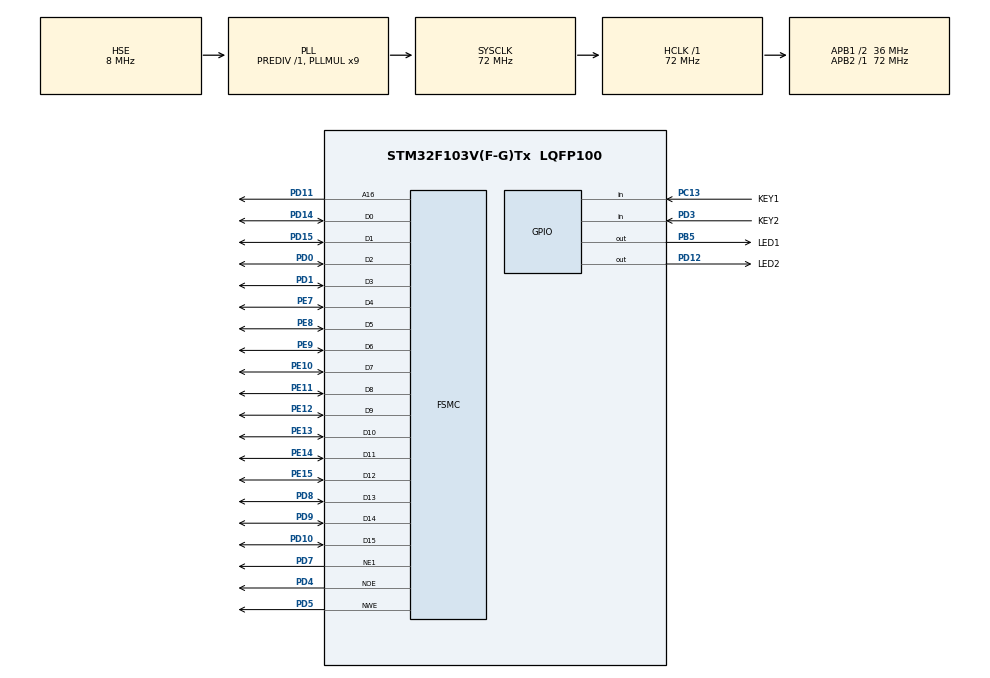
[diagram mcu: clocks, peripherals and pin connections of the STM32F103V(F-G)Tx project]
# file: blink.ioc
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FSMC.AddressSetupTime1=2
FSMC.BusTurnAroundDuration1=15
FSMC.DataSetupTime1=15
FSMC.ExtendedAddressSetupTime1=2
FSMC.ExtendedBusTurnAroundDuration1=1
FSMC.ExtendedDataSetupTime1=3
FSMC.ExtendedMode1=FSMC_EXTENDED_MODE_ENABLE
Mcu.Family=STM32F1
Mcu.Name=STM32F103V(F-G)Tx
Mcu.Package=LQFP100
NVIC.PriorityGroup=NVIC_PRIORITYGROUP_4
OSC_IN.Mode=HSE-External-Oscillator
OSC_IN.Signal=RCC_OSC_IN
OSC_OUT.Mode=HSE-External-Oscillator
OSC_OUT.Signal=RCC_OSC_OUT
PA13.Mode=Trace_Asynchronous_SW
PA13.Signal=SYS_JTMS-SWDIO
PA14.Mode=Trace_Asynchronous_SW
PA14.Signal=SYS_JTCK-SWCLK
PB3.Mode=Trace_Asynchronous_SW
PB3.Signal=SYS_JTDO-TRACESWO
PB5.GPIO_Label=LED1
PB5.GPIO_ModeDefaultOutputPP=GPIO_MODE_OUTPUT_PP
PB5.GPIO_PuPd=GPIO_NOPULL
PB5.GPIO_Speed=GPIO_SPEED_FREQ_LOW
PB5.PinState=GPIO_PIN_RESET
PB5.Signal=GPIO_Output
PC13-TAMPER-RTC.GPIO_Label=KEY1
PC13-TAMPER-RTC.GPIO_Mode=GPIO_MODE_INPUT
PC13-TAMPER-RTC.GPIO_PuPd=GPIO_PULLUP
PC13-TAMPER-RTC.Signal=GPIO_Input
PC14-OSC32_IN.Mode=LSE-External-Oscillator
PC14-OSC32_IN.Signal=RCC_OSC32_IN
PC15-OSC32_OUT.Mode=LSE-External-Oscillator
PC15-OSC32_OUT.Signal=RCC_OSC32_OUT
PD0.GPIO_Mode=GPIO_MODE_AF_PP
PD0.GPIO_Speed_High_Default=GPIO_SPEED_FREQ_HIGH
PD0.Mode=16b-d1
PD0.Signal=FSMC_D2
PD1.GPIO_Mode=GPIO_MODE_AF_PP
PD1.GPIO_Speed_High_Default=GPIO_SPEED_FREQ_HIGH
PD1.Mode=16b-d1
PD1.Signal=FSMC_D3
PD10.Mode=16b-d1
PD10.Signal=FSMC_D15
PD11.GPIO_Mode=GPIO_MODE_AF_PP
PD11.GPIO_Speed_High_Default=GPIO_SPEED_FREQ_HIGH
PD11.Mode=A16_1
PD11.Signal=FSMC_A16
PD12.GPIO_Label=LED2
PD12.GPIO_ModeDefaultOutputPP=GPIO_MODE_OUTPUT_PP
PD12.GPIO_PuPd=GPIO_NOPULL
PD12.GPIO_Speed=GPIO_SPEED_FREQ_LOW
PD12.PinState=GPIO_PIN_RESET
PD12.Signal=GPIO_Output
PD14.GPIO_Mode=GPIO_MODE_AF_PP
PD14.GPIO_Speed_High_Default=GPIO_SPEED_FREQ_HIGH
PD14.Mode=16b-d1
PD14.Signal=FSMC_D0
PD15.GPIO_Mode=GPIO_MODE_AF_PP
PD15.GPIO_Speed_High_Default=GPIO_SPEED_FREQ_HIGH
PD15.Mode=16b-d1
PD15.Signal=FSMC_D1
PD3.GPIO_Label=KEY2
PD3.GPIO_Mode=GPIO_MODE_INPUT
PD3.GPIO_PuPd=GPIO_PULLUP
PD3.Signal=GPIO_Input
PD4.GPIO_Mode=GPIO_MODE_AF_PP
PD4.GPIO_Speed_High_Default=GPIO_SPEED_FREQ_HIGH
PD4.Mode=Lcd1
PD4.Signal=FSMC_NOE
PD5.GPIO_Mode=GPIO_MODE_AF_PP
PD5.GPIO_Speed_High_Default=GPIO_SPEED_FREQ_HIGH
PD5.Mode=Lcd1
PD5.Signal=FSMC_NWE
PD7.GPIO_Mode=GPIO_MODE_AF_PP
PD7.GPIO_Speed_High_Default=GPIO_SPEED_FREQ_HIGH
PD7.Mode=NorPsramChipSelect1_1
PD7.Signal=FSMC_NE1
PD8.Mode=16b-d1
PD8.Signal=FSMC_D13
PD9.Mode=16b-d1
PD9.Signal=FSMC_D14
PE10.GPIO_Mode=GPIO_MODE_AF_PP
PE10.GPIO_Speed_High_Default=GPIO_SPEED_FREQ_HIGH
PE10.Mode=16b-d1
PE10.Signal=FSMC_D7
PE11.Mode=16b-d1
PE11.Signal=FSMC_D8
PE12.Mode=16b-d1
PE12.Signal=FSMC_D9
PE13.Mode=16b-d1
PE13.Signal=FSMC_D10
PE14.Mode=16b-d1
PE14.Signal=FSMC_D11
PE15.Mode=16b-d1
PE15.Signal=FSMC_D12
PE7.GPIO_Mode=GPIO_MODE_AF_PP
PE7.GPIO_Speed_High_Default=GPIO_SPEED_FREQ_HIGH
PE7.Mode=16b-d1
PE7.Signal=FSMC_D4
PE8.GPIO_Mode=GPIO_MODE_AF_PP
PE8.GPIO_Speed_High_Default=GPIO_SPEED_FREQ_HIGH
PE8.Mode=16b-d1
PE8.Signal=FSMC_D5
PE9.GPIO_Mode=GPIO_MODE_AF_PP
PE9.GPIO_Speed_High_Default=GPIO_SPEED_FREQ_HIGH
PE9.Mode=16b-d1
PE9.Signal=FSMC_D6
ProjectManager.HeapSize=0x200
ProjectManager.StackSize=0x400
ProjectManager.TargetToolchain=STM32CubeIDE
RCC.AHBFreq_Value=72000000
RCC.APB1CLKDivider=RCC_HCLK_DIV2
RCC.APB1Freq_Value=36000000
RCC.APB1TimFreq_Value=72000000
RCC.APB2Freq_Value=72000000
RCC.APB2TimFreq_Value=72000000
RCC.HCLKFreq_Value=72000000
RCC.PLLMUL=RCC_PLL_MUL9
RCC.PLLSourceVirtual=RCC_PLLSOURCE_HSE
RCC.SYSCLKFreq_VALUE=72000000
RCC.SYSCLKSource=RCC_SYSCLKSOURCE_PLLCLK
RCC.USBFreq_Value=72000000
board=custom

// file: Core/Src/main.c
/* USER CODE BEGIN Header */
/**
  ******************************************************************************
  * @file           : main.c
  * @brief          : Main program body
  ******************************************************************************
  * @attention
  *
  * <h2><center>&copy; Copyright (c) 2020 STMicroelectronics.
  * All rights reserved.</center></h2>
  *
  * This software component is licensed by ST under BSD 3-Clause license,
  * the "License"; You may not use this file except in compliance with the
  * License. You may obtain a copy of the License at:
  *                        opensource.org/licenses/BSD-3-Clause
  *
  ******************************************************************************
  */
/* USER CODE END Header */
#include "main.h"
#include "gpio.h"
#include "fsmc.h"

/* USER CODE BEGIN Includes */
#include "stdbool.h"
#include "math.h"
#include "stdlib.h"
#include "string.h"
#include "lcd_explay_n1.h"
/* USER CODE END Includes */

/* USER CODE BEGIN PV */
// SmallFont.c
// Modified by Alexey Stepanov (cyrillic symbols added)
// Font Size	: 8x12
// Memory usage	: 1720 bytes
// # characters	: 144
// offset       : 32
const uint8_t SmallFont[2008] ={
//0x08,0x0C,0x20,0x8F,
0x08,0x0C,0x20,0xA6,
0x00,0x00,0x00,0x00,0x00,0x00,0x00,0x00,0x00,0x00,0x00,0x00, // <Space>
0x00,0x00,0x20,0x20,0x20,0x20,0x20,0x20,0x00,0x20,0x00,0x00, // !
0x00,0x28,0x50,0x50,0x00,0x00,0x00,0x00,0x00,0x00,0x00,0x00, // "
0x00,0x00,0x28,0x28,0xFC,0x28,0x50,0xFC,0x50,0x50,0x00,0x00, // #
0x00,0x20,0x78,0xA8,0xA0,0x60,0x30,0x28,0xA8,0xF0,0x20,0x00, // $
0x00,0x00,0x48,0xA8,0xB0,0x50,0x28,0x34,0x54,0x48,0x00,0x00, // %
0x00,0x00,0x20,0x50,0x50,0x78,0xA8,0xA8,0x90,0x6C,0x00,0x00, // &
0x00,0x40,0x40,0x80,0x00,0x00,0x00,0x00,0x00,0x00,0x00,0x00, // '
0x00,0x04,0x08,0x10,0x10,0x10,0x10,0x10,0x10,0x08,0x04,0x00, // (
0x00,0x40,0x20,0x10,0x10,0x10,0x10,0x10,0x10,0x20,0x40,0x00, // )
0x00,0x00,0x00,0x20,0xA8,0x70,0x70,0xA8,0x20,0x00,0x00,0x00, // *
0x00,0x00,0x20,0x20,0x20,0xF8,0x20,0x20,0x20,0x00,0x00,0x00, // +
0x00,0x00,0x00,0x00,0x00,0x00,0x00,0x00,0x00,0x40,0x40,0x80, // ,
0x00,0x00,0x00,0x00,0x00,0xF8,0x00,0x00,0x00,0x00,0x00,0x00, // -
0x00,0x00,0x00,0x00,0x00,0x00,0x00,0x00,0x00,0x40,0x00,0x00, // .
0x00,0x08,0x10,0x10,0x10,0x20,0x20,0x40,0x40,0x40,0x80,0x00, // /
0x00,0x00,0x70,0x88,0x88,0x88,0x88,0x88,0x88,0x70,0x00,0x00, // 0
0x00,0x00,0x20,0x60,0x20,0x20,0x20,0x20,0x20,0x70,0x00,0x00, // 1
0x00,0x00,0x70,0x88,0x88,0x10,0x20,0x40,0x80,0xF8,0x00,0x00, // 2
0x00,0x00,0x70,0x88,0x08,0x30,0x08,0x08,0x88,0x70,0x00,0x00, // 3
0x00,0x00,0x10,0x30,0x50,0x50,0x90,0x78,0x10,0x18,0x00,0x00, // 4
0x00,0x00,0xF8,0x80,0x80,0xF0,0x08,0x08,0x88,0x70,0x00,0x00, // 5
0x00,0x00,0x70,0x90,0x80,0xF0,0x88,0x88,0x88,0x70,0x00,0x00, // 6
0x00,0x00,0xF8,0x90,0x10,0x20,0x20,0x20,0x20,0x20,0x00,0x00, // 7
0x00,0x00,0x70,0x88,0x88,0x70,0x88,0x88,0x88,0x70,0x00,0x00, // 8
0x00,0x00,0x70,0x88,0x88,0x88,0x78,0x08,0x48,0x70,0x00,0x00, // 9
0x00,0x00,0x00,0x00,0x20,0x00,0x00,0x00,0x00,0x20,0x00,0x00, // :
0x00,0x00,0x00,0x00,0x00,0x20,0x00,0x00,0x00,0x20,0x20,0x00, // ;
0x00,0x04,0x08,0x10,0x20,0x40,0x20,0x10,0x08,0x04,0x00,0x00, // <
0x00,0x00,0x00,0x00,0xF8,0x00,0x00,0xF8,0x00,0x00,0x00,0x00, // =
0x00,0x40,0x20,0x10,0x08,0x04,0x08,0x10,0x20,0x40,0x00,0x00, // >
0x00,0x00,0x70,0x88,0x88,0x10,0x20,0x20,0x00,0x20,0x00,0x00, // ?
0x00,0x00,0x70,0x88,0x98,0xA8,0xA8,0xB8,0x80,0x78,0x00,0x00, // @
0x00,0x00,0x20,0x20,0x30,0x50,0x50,0x78,0x48,0xCC,0x00,0x00, // A
0x00,0x00,0xF0,0x48,0x48,0x70,0x48,0x48,0x48,0xF0,0x00,0x00, // B
0x00,0x00,0x78,0x88,0x80,0x80,0x80,0x80,0x88,0x70,0x00,0x00, // C
0x00,0x00,0xF0,0x48,0x48,0x48,0x48,0x48,0x48,0xF0,0x00,0x00, // D
0x00,0x00,0xF8,0x48,0x50,0x70,0x50,0x40,0x48,0xF8,0x00,0x00, // E
0x00,0x00,0xF8,0x48,0x50,0x70,0x50,0x40,0x40,0xE0,0x00,0x00, // F
0x00,0x00,0x38,0x48,0x80,0x80,0x9C,0x88,0x48,0x30,0x00,0x00, // G
0x00,0x00,0xCC,0x48,0x48,0x78,0x48,0x48,0x48,0xCC,0x00,0x00, // H
0x00,0x00,0xF8,0x20,0x20,0x20,0x20,0x20,0x20,0xF8,0x00,0x00, // I
0x00,0x00,0x7C,0x10,0x10,0x10,0x10,0x10,0x10,0x90,0xE0,0x00, // J
0x00,0x00,0xEC,0x48,0x50,0x60,0x50,0x50,0x48,0xEC,0x00,0x00, // K
0x00,0x00,0xE0,0x40,0x40,0x40,0x40,0x40,0x44,0xFC,0x00,0x00, // L
0x00,0x00,0xD8,0xD8,0xD8,0xD8,0xA8,0xA8,0xA8,0xA8,0x00,0x00, // M
0x00,0x00,0xDC,0x48,0x68,0x68,0x58,0x58,0x48,0xE8,0x00,0x00, // N
0x00,0x00,0x70,0x88,0x88,0x88,0x88,0x88,0x88,0x70,0x00,0x00, // O
0x00,0x00,0xF0,0x48,0x48,0x70,0x40,0x40,0x40,0xE0,0x00,0x00, // P
0x00,0x00,0x70,0x88,0x88,0x88,0x88,0xE8,0x98,0x70,0x18,0x00, // Q
0x00,0x00,0xF0,0x48,0x48,0x70,0x50,0x48,0x48,0xEC,0x00,0x00, // R
0x00,0x00,0x78,0x88,0x80,0x60,0x10,0x08,0x88,0xF0,0x00,0x00, // S
0x00,0x00,0xF8,0xA8,0x20,0x20,0x20,0x20,0x20,0x70,0x00,0x00, // T
0x00,0x00,0xCC,0x48,0x48,0x48,0x48,0x48,0x48,0x30,0x00,0x00, // U
0x00,0x00,0xCC,0x48,0x48,0x50,0x50,0x30,0x20,0x20,0x00,0x00, // V
0x00,0x00,0xA8,0xA8,0xA8,0x70,0x50,0x50,0x50,0x50,0x00,0x00, // W
0x00,0x00,0xD8,0x50,0x50,0x20,0x20,0x50,0x50,0xD8,0x00,0x00, // X
0x00,0x00,0xD8,0x50,0x50,0x20,0x20,0x20,0x20,0x70,0x00,0x00, // Y
0x00,0x00,0xF8,0x90,0x10,0x20,0x20,0x40,0x48,0xF8,0x00,0x00, // Z
0x00,0x38,0x20,0x20,0x20,0x20,0x20,0x20,0x20,0x20,0x38,0x00, // [
0x00,0x40,0x40,0x40,0x20,0x20,0x10,0x10,0x10,0x08,0x00,0x00, // <Backslash>
0x00,0x70,0x10,0x10,0x10,0x10,0x10,0x10,0x10,0x10,0x70,0x00, // ]
0x00,0x20,0x50,0x00,0x00,0x00,0x00,0x00,0x00,0x00,0x00,0x00, // ^
0x00,0x00,0x00,0x00,0x00,0x00,0x00,0x00,0x00,0x00,0x00,0xFC, // _
0x00,0x20,0x00,0x00,0x00,0x00,0x00,0x00,0x00,0x00,0x00,0x00, // '
0x00,0x00,0x00,0x00,0x00,0x30,0x48,0x38,0x48,0x3C,0x00,0x00, // a
0x00,0x00,0xC0,0x40,0x40,0x70,0x48,0x48,0x48,0x70,0x00,0x00, // b
0x00,0x00,0x00,0x00,0x00,0x38,0x48,0x40,0x40,0x38,0x00,0x00, // c
0x00,0x00,0x18,0x08,0x08,0x38,0x48,0x48,0x48,0x3C,0x00,0x00, // d
0x00,0x00,0x00,0x00,0x00,0x30,0x48,0x78,0x40,0x38,0x00,0x00, // e
0x00,0x00,0x1C,0x20,0x20,0x78,0x20,0x20,0x20,0x78,0x00,0x00, // f
0x00,0x00,0x00,0x00,0x00,0x3C,0x48,0x30,0x40,0x78,0x44,0x38, // g
0x00,0x00,0xC0,0x40,0x40,0x70,0x48,0x48,0x48,0xEC,0x00,0x00, // h
0x00,0x00,0x20,0x00,0x00,0x60,0x20,0x20,0x20,0x70,0x00,0x00, // i
0x00,0x00,0x10,0x00,0x00,0x30,0x10,0x10,0x10,0x10,0x10,0xE0, // j
0x00,0x00,0xC0,0x40,0x40,0x5C,0x50,0x70,0x48,0xEC,0x00,0x00, // k
0x00,0x00,0xE0,0x20,0x20,0x20,0x20,0x20,0x20,0xF8,0x00,0x00, // l
0x00,0x00,0x00,0x00,0x00,0xF0,0xA8,0xA8,0xA8,0xA8,0x00,0x00, // m
0x00,0x00,0x00,0x00,0x00,0xF0,0x48,0x48,0x48,0xEC,0x00,0x00, // n
0x00,0x00,0x00,0x00,0x00,0x30,0x48,0x48,0x48,0x30,0x00,0x00, // o
0x00,0x00,0x00,0x00,0x00,0xF0,0x48,0x48,0x48,0x70,0x40,0xE0, // p
0x00,0x00,0x00,0x00,0x00,0x38,0x48,0x48,0x48,0x38,0x08,0x1C, // q
0x00,0x00,0x00,0x00,0x00,0xD8,0x60,0x40,0x40,0xE0,0x00,0x00, // r
0x00,0x00,0x00,0x00,0x00,0x78,0x40,0x30,0x08,0x78,0x00,0x00, // s
0x00,0x00,0x00,0x20,0x20,0x70,0x20,0x20,0x20,0x18,0x00,0x00, // t
0x00,0x00,0x00,0x00,0x00,0xD8,0x48,0x48,0x48,0x3C,0x00,0x00, // u
0x00,0x00,0x00,0x00,0x00,0xEC,0x48,0x50,0x30,0x20,0x00,0x00, // v
0x00,0x00,0x00,0x00,0x00,0xA8,0xA8,0x70,0x50,0x50,0x00,0x00, // w
0x00,0x00,0x00,0x00,0x00,0xD8,0x50,0x20,0x50,0xD8,0x00,0x00, // x
0x00,0x00,0x00,0x00,0x00,0xEC,0x48,0x50,0x30,0x20,0x20,0xC0, // y
0x00,0x00,0x00,0x00,0x00,0x78,0x10,0x20,0x20,0x78,0x00,0x00, // z
0x00,0x18,0x10,0x10,0x10,0x20,0x10,0x10,0x10,0x10,0x18,0x00, // {
0x10,0x10,0x10,0x10,0x10,0x10,0x10,0x10,0x10,0x10,0x10,0x10, // |
0x00,0x60,0x20,0x20,0x20,0x10,0x20,0x20,0x20,0x20,0x60,0x00, // }
0x40,0xA4,0x18,0x00,0x00,0x00,0x00,0x00,0x00,0x00,0x00,0x00, // ~
0x00,0x00,0x30,0x48,0x48,0x30,0x00,0x00,0x00,0x00,0x00,0x00, // градус 127	0x7F
0x00,0x00,0xF8,0x48,0x40,0x70,0x48,0x48,0x48,0xF0,0x00,0x00, // Б	128	0x80
0x00,0x00,0xF8,0x48,0x40,0x40,0x40,0x40,0x40,0xE0,0x00,0x00, // Г	129	0x81
0x00,0x00,0x38,0x48,0x48,0x48,0x48,0x48,0x48,0xFC,0x84,0x00, // Д	130	0x82
0x50,0x00,0xF8,0x48,0x50,0x70,0x50,0x40,0x48,0xF8,0x00,0x00, // Ё	131	0x83
0x00,0x00,0xA8,0xA8,0xA8,0x70,0xF8,0xA8,0xA8,0xA8,0x00,0x00, // Ж	132	0x84
0x00,0x00,0xF0,0x88,0x08,0x30,0x08,0x08,0x08,0xF0,0x00,0x00, // З	133	0x85
0x00,0x00,0xEC,0x48,0x58,0x58,0x68,0x68,0x48,0xDC,0x00,0x00, // �?	134	0x86
0x30,0x00,0xEC,0x48,0x58,0x58,0x68,0x68,0x48,0xDC,0x00,0x00, // Й	135	0x87
0x00,0x00,0x3C,0x48,0x48,0x48,0x48,0x48,0x48,0xCC,0x00,0x00, // Л	136	0x88
0x00,0x00,0xFC,0x48,0x48,0x48,0x48,0x48,0x48,0xCC,0x00,0x00, // П	137	0x89
0x00,0x00,0xD8,0x50,0x50,0x20,0x20,0x40,0x40,0x80,0x00,0x00, // У	138	0x8A
0x00,0x00,0x70,0xA8,0xA8,0xA8,0xA8,0x70,0x20,0x70,0x00,0x00, // Ф	139	0x8B
0x00,0x00,0xCC,0x48,0x48,0x48,0x48,0x48,0x48,0xFC,0x04,0x00, // Ц	140 0x8C
0x00,0x00,0xCC,0x48,0x48,0x48,0x38,0x08,0x08,0x1C,0x00,0x00, // Ч	141	0x8D
0x00,0x00,0xD6,0x54,0x54,0x54,0x54,0x54,0x54,0xFE,0x00,0x00, // Ш	142	0x8E
0x00,0x00,0xD6,0x54,0x54,0x54,0x54,0x54,0x54,0xFE,0x02,0x00, // Щ	143	0x8F
0x00,0x00,0xE0,0xC0,0x40,0x70,0x48,0x48,0x48,0xF0,0x00,0x00, // Ъ	144	0x90
0x00,0x00,0xEE,0x44,0x44,0x64,0x54,0x54,0x54,0xEE,0x00,0x00, // Ы	145	0x91
0x00,0x00,0xE0,0x40,0x40,0x70,0x48,0x48,0x48,0xF0,0x00,0x00, // Ь	146	0x92
0x00,0x00,0xE0,0x90,0x08,0x38,0x08,0x08,0x90,0x60,0x00,0x00, // Э	147	0x93
0x00,0x00,0xEC,0x52,0x52,0x52,0x72,0x52,0x52,0xEC,0x00,0x00, // Ю	148	0x94
0x00,0x00,0x3C,0x48,0x48,0x48,0x38,0x48,0x48,0x9C,0x00,0x00, // Я	149	0x95
0x00,0x00,0x08,0x30,0x40,0x70,0x48,0x48,0x48,0x30,0x00,0x00, // б	150	0x96
0x00,0x00,0x00,0x00,0x00,0x70,0x28,0x30,0x28,0x70,0x00,0x00, // в	151	0x97
0x00,0x00,0x00,0x00,0x00,0x78,0x28,0x20,0x20,0x70,0x00,0x00, // г	152	0x98
0x00,0x00,0x00,0x00,0x00,0x18,0x28,0x28,0x28,0x7C,0x44,0x00, // д	153	0x99
0x00,0x00,0x00,0x28,0x00,0x30,0x48,0x78,0x40,0x30,0x00,0x00, // ё	154	0x9A
0x00,0x00,0x00,0x00,0x00,0x54,0x54,0x38,0x54,0x54,0x00,0x00, // ж	155	0x9B
0x00,0x00,0x00,0x00,0x00,0x70,0x08,0x30,0x08,0x70,0x00,0x00, // з	156	0x9C
0x00,0x00,0x00,0x00,0x00,0xCC,0x48,0x58,0x68,0xCC,0x00,0x00, // и	157	0x9D
0x00,0x00,0x00,0x30,0x00,0xCC,0x48,0x58,0x68,0xCC,0x00,0x00, // й	158	0x9E
0x00,0x00,0x00,0x00,0x00,0x48,0x50,0x60,0x50,0x48,0x00,0x00, // к	159	0x9F
0x00,0x00,0x00,0x00,0x00,0x1C,0x28,0x28,0x28,0x4C,0x00,0x00, // л	160	0xA0
0x00,0x00,0x00,0x00,0x00,0x44,0x6C,0x54,0x44,0x44,0x00,0x00, // м	161	0xA1
0x00,0x00,0x00,0x00,0x00,0xCC,0x48,0x78,0x48,0xCC,0x00,0x00, // н	162	0xA2
0x00,0x00,0x00,0x00,0x00,0xFC,0x48,0x48,0x48,0xCC,0x00,0x00, // п	163	0xA3
0x00,0x00,0x00,0x00,0x00,0x7C,0x54,0x10,0x10,0x38,0x00,0x00, // т	164	0xA4
0x00,0x00,0x00,0x00,0x00,0x38,0x54,0x54,0x54,0x38,0x10,0x38, // ф	165	0xA5
0x00,0x00,0x00,0x00,0x00,0xCC,0x48,0x48,0x48,0xFC,0x04,0x00, // ц	166	0xA6
0x00,0x00,0x00,0x00,0x00,0xCC,0x48,0x38,0x08,0x0C,0x00,0x00, // ч	167	0xA7
0x00,0x00,0x00,0x00,0x00,0x54,0x54,0x54,0x54,0x7C,0x00,0x00, // ш	168	0xA8
0x00,0x00,0x00,0x00,0x00,0x54,0x54,0x54,0x54,0x7E,0x02,0x00, // щ	169	0xA9
0x00,0x00,0x00,0x00,0x00,0xE0,0xA0,0x30,0x28,0x70,0x00,0x00, // ъ	170	0xAA
0x00,0x00,0x00,0x00,0x00,0xC6,0x44,0x64,0x54,0xE6,0x00,0x00, // ы	171	0xAB
0x00,0x00,0x00,0x00,0x00,0x60,0x20,0x30,0x28,0x70,0x00,0x00, // ь	172	0xAC
0x00,0x00,0x00,0x00,0x00,0x30,0x48,0x18,0x48,0x30,0x00,0x00, // э	173	0xAD
0x00,0x00,0x00,0x00,0x00,0xC8,0x54,0x74,0x54,0xC8,0x00,0x00, // ю	174	0xAE
0x00,0x00,0x00,0x00,0x00,0x3C,0x48,0x48,0x38,0x4C,0x00,0x00, // я	175	0xAF
0x3C,0xE7,0x81,0xBD,0x81,0xBD,0x81,0xBD,0x81,0xBD,0x81,0xFF, // BATT FULL	176	0xB0
0x3C,0xE7,0x81,0x81,0x81,0xBD,0x81,0xBD,0x81,0xBD,0x81,0xFF, // BATT 75%	177	0xB1
0x3C,0xE7,0x81,0x81,0x81,0x81,0x81,0xBD,0x81,0xBD,0x81,0xFF, // BATT 50%	178	0xB2
0x3C,0xE7,0x81,0x81,0x81,0x81,0x81,0x81,0x81,0xBD,0x81,0xFF, // BATT 25%	179	0xB3
0x3C,0xE7,0x81,0x81,0x81,0x81,0x81,0x81,0x81,0x81,0x81,0xFF, // BATT EMPTY	180	0xB4
0xFF,0xFF,0x00,0x3F,0x3F,0x00,0x0F,0x0F,0x00,0x03,0x03,0x00, // сингал 100%	181	0xB5
0x00,0x00,0x00,0x3F,0x3F,0x00,0x0F,0x0F,0x00,0x03,0x03,0x00, // сигнал 75%	182	0xB6
0x00,0x00,0x00,0x00,0x00,0x00,0x0F,0x0F,0x00,0x03,0x03,0x00, // сигнал 50%	183	0xB7
0x00,0x00,0x00,0x00,0x00,0x00,0x00,0x00,0x00,0x03,0x03,0x00, // сигнал 25%	184	0xB8
0x00,0x00,0x10,0x10,0x10,0x10,0x10,0x54,0x38,0x10,0x00,0x00, // стрелка вверх	185	0xB9
0x00,0x00,0x10,0x38,0x54,0x10,0x10,0x10,0x10,0x10,0x00,0x00, // стрелка вниз	186	0xBA
0x00,0x00,0x00,0x00,0x10,0x08,0x7C,0x08,0x10,0x00,0x00,0x00, // стрелка вправо	187	0xBB
0x00,0x00,0x00,0x00,0x10,0x20,0x7C,0x20,0x10,0x00,0x00,0x00, // стрелка влево	188	0xBC
0x00,0x00,0x00,0x3C,0x0C,0x14,0x24,0x44,0x80,0x00,0x00,0x00, // стрелка вверх вправо	189	0xBD
0x00,0x00,0x00,0x80,0x44,0x24,0x14,0x0C,0x3C,0x00,0x00,0x00, // стрелка вниз вправо	190	0xBE
0x00,0x00,0x3C,0x42,0xA5,0x81,0xA5,0x99,0x42,0x3C,0x00,0x00, // веселый смайл	191	0xBF
0x00,0x00,0x3C,0x7E,0xDB,0xFF,0xFF,0xDB,0x66,0x3C,0x00,0x00, // веселый негр 192	0xC0
0x00,0x00,0x3C,0x42,0xA5,0x81,0x99,0xA5,0x42,0x3C,0x00,0x00, // грустный смайл 	193	0xC1
0x00,0x00,0x3C,0x7E,0xDB,0xFF,0xFF,0xE7,0x5A,0x3C,0x00,0x00, // грустный негр 194	0xC2
0x00,0x00,0x3C,0x42,0x81,0x81,0x81,0x81,0x42,0x3C,0x00,0x00, // пустой круг	195	0xC3
0x00,0x00,0x3C,0x7E,0xFF,0xFF,0xFF,0xFF,0x7E,0x3C,0x00,0x00, // полный круг 196	0xC4
0x00,0x00,0xFF,0x81,0x81,0x81,0x81,0x81,0x81,0xFF,0x00,0x00, // квадрат пустой 197	0xC5
0x00,0x00,0xFF,0xFF,0xFF,0xFF,0xFF,0xFF,0xFF,0xFF,0x00,0x00, // квадрат полный 198	0xC6
};

// BigFont.c (C)2010 by Henning Karlsen
// Font Size	: 16x16
// Memory usage	: 3044 bytes
// # characters	: 95
const uint8_t BigFont[4612] ={
0x10,0x10,0x20,0x8F,
0x00,0x00,0x00,0x00,0x00,0x00,0x00,0x00,0x00,0x00,0x00,0x00,0x00,0x00,0x00,0x00,0x00,0x00,0x00,0x00,0x00,0x00,0x00,0x00,0x00,0x00,0x00,0x00,0x00,0x00,0x00,0x00, //  <Space>
0x00,0x00,0x00,0x00,0x07,0x00,0x0F,0x80,0x0F,0x80,0x0F,0x80,0x0F,0x80,0x0F,0x80,0x07,0x00,0x07,0x00,0x00,0x00,0x00,0x00,0x07,0x00,0x07,0x00,0x07,0x00,0x00,0x00, // !
0x00,0x00,0x0E,0x38,0x0E,0x38,0x0E,0x38,0x0E,0x38,0x06,0x30,0x00,0x00,0x00,0x00,0x00,0x00,0x00,0x00,0x00,0x00,0x00,0x00,0x00,0x00,0x00,0x00,0x00,0x00,0x00,0x00, // "
0x00,0x00,0x0C,0x30,0x0C,0x30,0x0C,0x30,0x7F,0xFE,0x7F,0xFE,0x0C,0x30,0x0C,0x30,0x0C,0x30,0x0C,0x30,0x7F,0xFE,0x7F,0xFE,0x0C,0x30,0x0C,0x30,0x0C,0x30,0x00,0x00, // #
0x00,0x00,0x02,0x40,0x02,0x40,0x0F,0xF8,0x1F,0xF8,0x1A,0x40,0x1A,0x40,0x1F,0xF0,0x0F,0xF8,0x02,0x58,0x02,0x58,0x1F,0xF8,0x1F,0xF0,0x02,0x40,0x02,0x40,0x00,0x00, // $
0x00,0x00,0x00,0x00,0x00,0x00,0x0E,0x10,0x0E,0x30,0x0E,0x70,0x00,0xE0,0x01,0xC0,0x03,0x80,0x07,0x00,0x0E,0x70,0x0C,0x70,0x08,0x70,0x00,0x00,0x00,0x00,0x00,0x00, // %
0x00,0x00,0x00,0x00,0x0F,0x00,0x19,0x80,0x19,0x80,0x19,0x80,0x0F,0x00,0x0F,0x08,0x0F,0x98,0x19,0xF8,0x18,0xF0,0x18,0xE0,0x19,0xF0,0x0F,0x98,0x00,0x00,0x00,0x00, // &
0x00,0x00,0x00,0x00,0x07,0x00,0x07,0x00,0x07,0x00,0x0E,0x00,0x00,0x00,0x00,0x00,0x00,0x00,0x00,0x00,0x00,0x00,0x00,0x00,0x00,0x00,0x00,0x00,0x00,0x00,0x00,0x00, // '
0x00,0x00,0x00,0x00,0x00,0xF0,0x01,0xC0,0x03,0x80,0x07,0x00,0x0E,0x00,0x0E,0x00,0x0E,0x00,0x0E,0x00,0x07,0x00,0x03,0x80,0x01,0xC0,0x00,0xF0,0x00,0x00,0x00,0x00, // (
0x00,0x00,0x00,0x00,0x0F,0x00,0x03,0x80,0x01,0xC0,0x00,0xE0,0x00,0x70,0x00,0x70,0x00,0x70,0x00,0x70,0x00,0xE0,0x01,0xC0,0x03,0x80,0x0F,0x00,0x00,0x00,0x00,0x00, // )
0x00,0x00,0x00,0x00,0x01,0x80,0x11,0x88,0x09,0x90,0x07,0xE0,0x07,0xE0,0x3F,0xFC,0x3F,0xFC,0x07,0xE0,0x07,0xE0,0x09,0x90,0x11,0x88,0x01,0x80,0x00,0x00,0x00,0x00, // *
0x00,0x00,0x00,0x00,0x00,0x00,0x00,0x00,0x01,0x80,0x01,0x80,0x01,0x80,0x0F,0xF0,0x0F,0xF0,0x01,0x80,0x01,0x80,0x01,0x80,0x00,0x00,0x00,0x00,0x00,0x00,0x00,0x00, // +
0x00,0x00,0x00,0x00,0x00,0x00,0x00,0x00,0x00,0x00,0x00,0x00,0x00,0x00,0x00,0x00,0x00,0x00,0x00,0x00,0x00,0x00,0x07,0x00,0x07,0x00,0x07,0x00,0x0E,0x00,0x00,0x00, // ,
0x00,0x00,0x00,0x00,0x00,0x00,0x00,0x00,0x00,0x00,0x00,0x00,0x00,0x00,0x1F,0xF8,0x1F,0xF8,0x00,0x00,0x00,0x00,0x00,0x00,0x00,0x00,0x00,0x00,0x00,0x00,0x00,0x00, // -
0x00,0x00,0x00,0x00,0x00,0x00,0x00,0x00,0x00,0x00,0x00,0x00,0x00,0x00,0x00,0x00,0x00,0x00,0x00,0x00,0x00,0x00,0x07,0x00,0x07,0x00,0x07,0x00,0x00,0x00,0x00,0x00, // ,
0x00,0x00,0x00,0x00,0x00,0x02,0x00,0x06,0x00,0x0E,0x00,0x1C,0x00,0x38,0x00,0x70,0x00,0xE0,0x01,0xC0,0x03,0x80,0x07,0x00,0x0E,0x00,0x1C,0x00,0x00,0x00,0x00,0x00, // /
0x00,0x00,0x00,0x00,0x0F,0xF0,0x1C,0x38,0x1C,0x78,0x1C,0xF8,0x1C,0xF8,0x1D,0xB8,0x1D,0xB8,0x1F,0x38,0x1F,0x38,0x1E,0x38,0x1C,0x38,0x0F,0xF0,0x00,0x00,0x00,0x00, // 0
0x00,0x00,0x00,0x00,0x01,0x80,0x01,0x80,0x03,0x80,0x1F,0x80,0x1F,0x80,0x03,0x80,0x03,0x80,0x03,0x80,0x03,0x80,0x03,0x80,0x03,0x80,0x1F,0xF0,0x00,0x00,0x00,0x00, // 1
0x00,0x00,0x00,0x00,0x0F,0xE0,0x1C,0x70,0x1C,0x38,0x00,0x38,0x00,0x70,0x00,0xE0,0x01,0xC0,0x03,0x80,0x07,0x00,0x0E,0x38,0x1C,0x38,0x1F,0xF8,0x00,0x00,0x00,0x00, // 2
0x00,0x00,0x00,0x00,0x0F,0xE0,0x1C,0x70,0x1C,0x38,0x00,0x38,0x00,0x70,0x03,0xC0,0x03,0xC0,0x00,0x70,0x00,0x38,0x1C,0x38,0x1C,0x70,0x0F,0xE0,0x00,0x00,0x00,0x00, // 3
0x00,0x00,0x00,0x00,0x00,0xE0,0x01,0xE0,0x03,0xE0,0x06,0xE0,0x0C,0xE0,0x18,0xE0,0x1F,0xF8,0x1F,0xF8,0x00,0xE0,0x00,0xE0,0x00,0xE0,0x03,0xF8,0x00,0x00,0x00,0x00, // 4
0x00,0x00,0x00,0x00,0x1F,0xF8,0x1C,0x00,0x1C,0x00,0x1C,0x00,0x1C,0x00,0x1F,0xE0,0x1F,0xF0,0x00,0x78,0x00,0x38,0x1C,0x38,0x1C,0x70,0x0F,0xE0,0x00,0x00,0x00,0x00, // 5
0x00,0x00,0x00,0x00,0x03,0xE0,0x07,0x00,0x0E,0x00,0x1C,0x00,0x1C,0x00,0x1F,0xF0,0x1F,0xF8,0x1C,0x38,0x1C,0x38,0x1C,0x38,0x1C,0x38,0x0F,0xF0,0x00,0x00,0x00,0x00, // 6
0x00,0x00,0x00,0x00,0x1F,0xFC,0x1C,0x1C,0x1C,0x1C,0x1C,0x1C,0x00,0x1C,0x00,0x38,0x00,0x70,0x00,0xE0,0x01,0xC0,0x03,0x80,0x03,0x80,0x03,0x80,0x00,0x00,0x00,0x00, // 7
0x00,0x00,0x00,0x00,0x0F,0xF0,0x1C,0x38,0x1C,0x38,0x1C,0x38,0x1F,0x38,0x07,0xE0,0x07,0xE0,0x1C,0xF8,0x1C,0x38,0x1C,0x38,0x1C,0x38,0x0F,0xF0,0x00,0x00,0x00,0x00, // 8
0x00,0x00,0x00,0x00,0x0F,0xF0,0x1C,0x38,0x1C,0x38,0x1C,0x38,0x1C,0x38,0x1F,0xF8,0x0F,0xF8,0x00,0x38,0x00,0x38,0x00,0x70,0x00,0xE0,0x07,0xC0,0x00,0x00,0x00,0x00, // 9
0x00,0x00,0x00,0x00,0x00,0x00,0x00,0x00,0x03,0x80,0x03,0x80,0x03,0x80,0x00,0x00,0x00,0x00,0x03,0x80,0x03,0x80,0x03,0x80,0x00,0x00,0x00,0x00,0x00,0x00,0x00,0x00, // :
0x00,0x00,0x00,0x00,0x00,0x00,0x00,0x00,0x03,0x80,0x03,0x80,0x03,0x80,0x00,0x00,0x00,0x00,0x03,0x80,0x03,0x80,0x03,0x80,0x07,0x00,0x00,0x00,0x00,0x00,0x00,0x00, // ;
0x00,0x00,0x00,0x70,0x00,0xE0,0x01,0xC0,0x03,0x80,0x07,0x00,0x0E,0x00,0x1C,0x00,0x1C,0x00,0x0E,0x00,0x07,0x00,0x03,0x80,0x01,0xC0,0x00,0xE0,0x00,0x70,0x00,0x00, // <
0x00,0x00,0x00,0x00,0x00,0x00,0x00,0x00,0x00,0x00,0x3F,0xFC,0x3F,0xFC,0x00,0x00,0x00,0x00,0x3F,0xFC,0x3F,0xFC,0x00,0x00,0x00,0x00,0x00,0x00,0x00,0x00,0x00,0x00, // =
0x00,0x00,0x1C,0x00,0x0E,0x00,0x07,0x00,0x03,0x80,0x01,0xC0,0x00,0xE0,0x00,0x70,0x00,0x70,0x00,0xE0,0x01,0xC0,0x03,0x80,0x07,0x00,0x0E,0x00,0x1C,0x00,0x00,0x00, // >
0x00,0x00,0x03,0xC0,0x0F,0xF0,0x1E,0x78,0x18,0x38,0x00,0x38,0x00,0x70,0x00,0xE0,0x01,0xC0,0x01,0xC0,0x00,0x00,0x00,0x00,0x01,0xC0,0x01,0xC0,0x01,0xC0,0x00,0x00, // ?
0x00,0x00,0x0F,0xF8,0x1C,0x1C,0x1C,0x1C,0x1C,0x1C,0x1C,0x1C,0x1C,0xFC,0x1C,0xFC,0x1C,0xFC,0x1C,0xFC,0x1C,0x00,0x1C,0x00,0x1C,0x00,0x1F,0xF0,0x07,0xF8,0x00,0x00, // @
0x00,0x00,0x00,0x00,0x03,0xC0,0x07,0xE0,0x0E,0x70,0x1C,0x38,0x1C,0x38,0x1C,0x38,0x1C,0x38,0x1F,0xF8,0x1C,0x38,0x1C,0x38,0x1C,0x38,0x1C,0x38,0x00,0x00,0x00,0x00, // A
0x00,0x00,0x00,0x00,0x1F,0xF0,0x0E,0x38,0x0E,0x38,0x0E,0x38,0x0E,0x38,0x0F,0xF0,0x0F,0xF0,0x0E,0x38,0x0E,0x38,0x0E,0x38,0x0E,0x38,0x1F,0xF0,0x00,0x00,0x00,0x00, // B
0x00,0x00,0x00,0x00,0x07,0xF0,0x0E,0x38,0x1C,0x38,0x1C,0x00,0x1C,0x00,0x1C,0x00,0x1C,0x00,0x1C,0x00,0x1C,0x00,0x1C,0x38,0x0E,0x38,0x07,0xF0,0x00,0x00,0x00,0x00, // C
0x00,0x00,0x00,0x00,0x1F,0xE0,0x0E,0x70,0x0E,0x38,0x0E,0x38,0x0E,0x38,0x0E,0x38,0x0E,0x38,0x0E,0x38,0x0E,0x38,0x0E,0x38,0x0E,0x70,0x1F,0xE0,0x00,0x00,0x00,0x00, // D
0x00,0x00,0x00,0x00,0x1F,0xF8,0x0E,0x18,0x0E,0x08,0x0E,0x00,0x0E,0x30,0x0F,0xF0,0x0F,0xF0,0x0E,0x30,0x0E,0x00,0x0E,0x08,0x0E,0x18,0x1F,0xF8,0x00,0x00,0x00,0x00, // E
0x00,0x00,0x00,0x00,0x1F,0xF8,0x0E,0x18,0x0E,0x08,0x0E,0x00,0x0E,0x30,0x0F,0xF0,0x0F,0xF0,0x0E,0x30,0x0E,0x00,0x0E,0x00,0x0E,0x00,0x1F,0x00,0x00,0x00,0x00,0x00, // F
0x00,0x00,0x00,0x00,0x07,0xF0,0x0E,0x38,0x1C,0x38,0x1C,0x38,0x1C,0x00,0x1C,0x00,0x1C,0x00,0x1C,0xF8,0x1C,0x38,0x1C,0x38,0x0E,0x38,0x07,0xF8,0x00,0x00,0x00,0x00, // G
0x00,0x00,0x00,0x00,0x1C,0x70,0x1C,0x70,0x1C,0x70,0x1C,0x70,0x1C,0x70,0x1F,0xF0,0x1F,0xF0,0x1C,0x70,0x1C,0x70,0x1C,0x70,0x1C,0x70,0x1C,0x70,0x00,0x00,0x00,0x00, // H
0x00,0x00,0x00,0x00,0x0F,0xE0,0x03,0x80,0x03,0x80,0x03,0x80,0x03,0x80,0x03,0x80,0x03,0x80,0x03,0x80,0x03,0x80,0x03,0x80,0x03,0x80,0x0F,0xE0,0x00,0x00,0x00,0x00, // I
0x00,0x00,0x00,0x00,0x01,0xFC,0x00,0x70,0x00,0x70,0x00,0x70,0x00,0x70,0x00,0x70,0x00,0x70,0x38,0x70,0x38,0x70,0x38,0x70,0x38,0x70,0x0F,0xE0,0x00,0x00,0x00,0x00, // J
0x00,0x00,0x00,0x00,0x1E,0x38,0x0E,0x38,0x0E,0x70,0x0E,0xE0,0x0F,0xC0,0x0F,0x80,0x0F,0x80,0x0F,0xC0,0x0E,0xE0,0x0E,0x70,0x0E,0x38,0x1E,0x38,0x00,0x00,0x00,0x00, // K
0x00,0x00,0x00,0x00,0x1F,0x00,0x0E,0x00,0x0E,0x00,0x0E,0x00,0x0E,0x00,0x0E,0x00,0x0E,0x00,0x0E,0x00,0x0E,0x08,0x0E,0x18,0x0E,0x38,0x1F,0xF8,0x00,0x00,0x00,0x00, // L
0x00,0x00,0x00,0x00,0x1C,0x1C,0x1E,0x3C,0x1F,0x7C,0x1F,0xFC,0x1F,0xFC,0x1D,0xDC,0x1C,0x9C,0x1C,0x1C,0x1C,0x1C,0x1C,0x1C,0x1C,0x1C,0x1C,0x1C,0x00,0x00,0x00,0x00, // M
0x00,0x00,0x00,0x00,0x1C,0x1C,0x1C,0x1C,0x1E,0x1C,0x1F,0x1C,0x1F,0x9C,0x1D,0xDC,0x1C,0xFC,0x1C,0x7C,0x1C,0x3C,0x1C,0x1C,0x1C,0x1C,0x1C,0x1C,0x00,0x00,0x00,0x00, // N
0x00,0x00,0x00,0x00,0x03,0xE0,0x07,0xF0,0x0E,0x38,0x1C,0x1C,0x1C,0x1C,0x1C,0x1C,0x1C,0x1C,0x1C,0x1C,0x1C,0x1C,0x0E,0x38,0x07,0xF0,0x03,0xE0,0x00,0x00,0x00,0x00, // O
0x00,0x00,0x00,0x00,0x1F,0xF0,0x0E,0x38,0x0E,0x38,0x0E,0x38,0x0E,0x38,0x0F,0xF0,0x0F,0xF0,0x0E,0x00,0x0E,0x00,0x0E,0x00,0x0E,0x00,0x1F,0x00,0x00,0x00,0x00,0x00, // P
0x00,0x00,0x00,0x00,0x03,0xE0,0x0F,0x78,0x0E,0x38,0x1C,0x1C,0x1C,0x1C,0x1C,0x1C,0x1C,0x1C,0x1C,0x7C,0x1C,0xFC,0x0F,0xF8,0x0F,0xF8,0x00,0x38,0x00,0xFC,0x00,0x00, // Q
0x00,0x00,0x00,0x00,0x1F,0xF0,0x0E,0x38,0x0E,0x38,0x0E,0x38,0x0E,0x38,0x0F,0xF0,0x0F,0xF0,0x0E,0x70,0x0E,0x38,0x0E,0x38,0x0E,0x38,0x1E,0x38,0x00,0x00,0x00,0x00, // R
0x00,0x00,0x00,0x00,0x0F,0xF0,0x1C,0x38,0x1C,0x38,0x1C,0x38,0x1C,0x00,0x0F,0xE0,0x07,0xF0,0x00,0x38,0x1C,0x38,0x1C,0x38,0x1C,0x38,0x0F,0xF0,0x00,0x00,0x00,0x00, // S
0x00,0x00,0x00,0x00,0x1F,0xFC,0x19,0xCC,0x11,0xC4,0x01,0xC0,0x01,0xC0,0x01,0xC0,0x01,0xC0,0x01,0xC0,0x01,0xC0,0x01,0xC0,0x01,0xC0,0x07,0xF0,0x00,0x00,0x00,0x00, // T
0x00,0x00,0x00,0x00,0x1C,0x70,0x1C,0x70,0x1C,0x70,0x1C,0x70,0x1C,0x70,0x1C,0x70,0x1C,0x70,0x1C,0x70,0x1C,0x70,0x1C,0x70,0x1C,0x70,0x0F,0xE0,0x00,0x00,0x00,0x00, // U
0x00,0x00,0x00,0x00,0x1C,0x70,0x1C,0x70,0x1C,0x70,0x1C,0x70,0x1C,0x70,0x1C,0x70,0x1C,0x70,0x1C,0x70,0x1C,0x70,0x0E,0xE0,0x07,0xC0,0x03,0x80,0x00,0x00,0x00,0x00, // V
0x00,0x00,0x00,0x00,0x1C,0x1C,0x1C,0x1C,0x1C,0x1C,0x1C,0x1C,0x1C,0x1C,0x1C,0x9C,0x1C,0x9C,0x1C,0x9C,0x0F,0xF8,0x0F,0xF8,0x07,0x70,0x07,0x70,0x00,0x00,0x00,0x00, // W
0x00,0x00,0x00,0x00,0x1C,0x70,0x1C,0x70,0x1C,0x70,0x0E,0xE0,0x07,0xC0,0x03,0x80,0x03,0x80,0x07,0xC0,0x0E,0xE0,0x1C,0x70,0x1C,0x70,0x1C,0x70,0x00,0x00,0x00,0x00, // X
0x00,0x00,0x00,0x00,0x1C,0x70,0x1C,0x70,0x1C,0x70,0x1C,0x70,0x1C,0x70,0x0E,0xE0,0x07,0xC0,0x03,0x80,0x03,0x80,0x03,0x80,0x03,0x80,0x0F,0xE0,0x00,0x00,0x00,0x00, // Y
0x00,0x00,0x00,0x00,0x1F,0xF8,0x1C,0x38,0x18,0x38,0x10,0x70,0x00,0xE0,0x01,0xC0,0x03,0x80,0x07,0x00,0x0E,0x08,0x1C,0x18,0x1C,0x38,0x1F,0xF8,0x00,0x00,0x00,0x00, // Z
0x00,0x00,0x00,0x00,0x07,0xF0,0x07,0x00,0x07,0x00,0x07,0x00,0x07,0x00,0x07,0x00,0x07,0x00,0x07,0x00,0x07,0x00,0x07,0x00,0x07,0x00,0x07,0xF0,0x00,0x00,0x00,0x00, // [
0x00,0x00,0x00,0x00,0x10,0x00,0x18,0x00,0x1C,0x00,0x0E,0x00,0x07,0x00,0x03,0x80,0x01,0xC0,0x00,0xE0,0x00,0x70,0x00,0x38,0x00,0x1C,0x00,0x07,0x00,0x00,0x00,0x00, // <Backslash>
0x00,0x00,0x00,0x00,0x07,0xF0,0x00,0x70,0x00,0x70,0x00,0x70,0x00,0x70,0x00,0x70,0x00,0x70,0x00,0x70,0x00,0x70,0x00,0x70,0x00,0x70,0x07,0xF0,0x00,0x00,0x00,0x00, // ]
0x00,0x00,0x01,0x80,0x03,0xC0,0x07,0xE0,0x0E,0x70,0x1C,0x38,0x00,0x00,0x00,0x00,0x00,0x00,0x00,0x00,0x00,0x00,0x00,0x00,0x00,0x00,0x00,0x00,0x00,0x00,0x00,0x00, // ^
0x00,0x00,0x00,0x00,0x00,0x00,0x00,0x00,0x00,0x00,0x00,0x00,0x00,0x00,0x00,0x00,0x00,0x00,0x00,0x00,0x00,0x00,0x00,0x00,0x00,0x00,0x00,0x00,0x7F,0xFF,0x7F,0xFF, // _
0x00,0x00,0x00,0x00,0x1C,0x00,0x1C,0x00,0x07,0x00,0x07,0x00,0x00,0x00,0x00,0x00,0x00,0x00,0x00,0x00,0x00,0x00,0x00,0x00,0x00,0x00,0x00,0x00,0x00,0x00,0x00,0x00, // '
0x00,0x00,0x00,0x00,0x00,0x00,0x00,0x00,0x00,0x00,0x00,0x00,0x0F,0xE0,0x00,0x70,0x00,0x70,0x0F,0xF0,0x1C,0x70,0x1C,0x70,0x1C,0x70,0x0F,0xD8,0x00,0x00,0x00,0x00, // a
0x00,0x00,0x00,0x00,0x1E,0x00,0x0E,0x00,0x0E,0x00,0x0E,0x00,0x0F,0xF0,0x0E,0x38,0x0E,0x38,0x0E,0x38,0x0E,0x38,0x0E,0x38,0x0E,0x38,0x1B,0xF0,0x00,0x00,0x00,0x00, // b
0x00,0x00,0x00,0x00,0x00,0x00,0x00,0x00,0x00,0x00,0x00,0x00,0x0F,0xE0,0x1C,0x70,0x1C,0x70,0x1C,0x00,0x1C,0x00,0x1C,0x70,0x1C,0x70,0x0F,0xE0,0x00,0x00,0x00,0x00, // c
0x00,0x00,0x00,0x00,0x00,0xF8,0x00,0x70,0x00,0x70,0x00,0x70,0x0F,0xF0,0x1C,0x70,0x1C,0x70,0x1C,0x70,0x1C,0x70,0x1C,0x70,0x1C,0x70,0x0F,0xD8,0x00,0x00,0x00,0x00, // d
0x00,0x00,0x00,0x00,0x00,0x00,0x00,0x00,0x00,0x00,0x00,0x00,0x0F,0xE0,0x1C,0x70,0x1C,0x70,0x1F,0xF0,0x1C,0x00,0x1C,0x70,0x1C,0x70,0x0F,0xE0,0x00,0x00,0x00,0x00, // e
0x00,0x00,0x00,0x00,0x03,0xE0,0x07,0x70,0x07,0x70,0x07,0x00,0x07,0x00,0x1F,0xE0,0x1F,0xE0,0x07,0x00,0x07,0x00,0x07,0x00,0x07,0x00,0x1F,0xC0,0x00,0x00,0x00,0x00, // f
0x00,0x00,0x00,0x00,0x00,0x00,0x00,0x00,0x00,0x00,0x00,0x00,0x0F,0xD8,0x1C,0x70,0x1C,0x70,0x1C,0x70,0x1C,0x70,0x0F,0xF0,0x07,0xF0,0x00,0x70,0x1C,0x70,0x0F,0xE0, // g
0x00,0x00,0x00,0x00,0x1E,0x00,0x0E,0x00,0x0E,0x00,0x0E,0x00,0x0E,0xF0,0x0F,0x38,0x0F,0x38,0x0E,0x38,0x0E,0x38,0x0E,0x38,0x0E,0x38,0x1E,0x38,0x00,0x00,0x00,0x00, // h
0x00,0x00,0x00,0x00,0x01,0xC0,0x01,0xC0,0x01,0xC0,0x00,0x00,0x0F,0xC0,0x01,0xC0,0x01,0xC0,0x01,0xC0,0x01,0xC0,0x01,0xC0,0x01,0xC0,0x0F,0xF8,0x00,0x00,0x00,0x00, // i
0x00,0x00,0x00,0x00,0x00,0x70,0x00,0x70,0x00,0x70,0x00,0x00,0x03,0xF0,0x00,0x70,0x00,0x70,0x00,0x70,0x00,0x70,0x00,0x70,0x00,0x70,0x1C,0x70,0x0C,0xF0,0x07,0xE0, // j
0x00,0x00,0x00,0x00,0x1E,0x00,0x0E,0x00,0x0E,0x00,0x0E,0x00,0x0E,0x38,0x0E,0x70,0x0E,0xE0,0x0F,0xC0,0x0E,0xE0,0x0E,0x70,0x0E,0x38,0x1E,0x38,0x00,0x00,0x00,0x00, // k
0x00,0x00,0x00,0x00,0x0F,0xC0,0x01,0xC0,0x01,0xC0,0x01,0xC0,0x01,0xC0,0x01,0xC0,0x01,0xC0,0x01,0xC0,0x01,0xC0,0x01,0xC0,0x01,0xC0,0x0F,0xF8,0x00,0x00,0x00,0x00, // l
0x00,0x00,0x00,0x00,0x00,0x00,0x00,0x00,0x00,0x00,0x00,0x00,0x1F,0xF8,0x1C,0x9C,0x1C,0x9C,0x1C,0x9C,0x1C,0x9C,0x1C,0x9C,0x1C,0x9C,0x1C,0x9C,0x00,0x00,0x00,0x00, // m
0x00,0x00,0x00,0x00,0x00,0x00,0x00,0x00,0x00,0x00,0x00,0x00,0x1F,0xE0,0x1C,0x70,0x1C,0x70,0x1C,0x70,0x1C,0x70,0x1C,0x70,0x1C,0x70,0x1C,0x70,0x00,0x00,0x00,0x00, // n
0x00,0x00,0x00,0x00,0x00,0x00,0x00,0x00,0x00,0x00,0x00,0x00,0x0F,0xE0,0x1C,0x70,0x1C,0x70,0x1C,0x70,0x1C,0x70,0x1C,0x70,0x1C,0x70,0x0F,0xE0,0x00,0x00,0x00,0x00, // o
0x00,0x00,0x00,0x00,0x00,0x00,0x00,0x00,0x00,0x00,0x00,0x00,0x1B,0xF0,0x0E,0x38,0x0E,0x38,0x0E,0x38,0x0E,0x38,0x0E,0x38,0x0F,0xF0,0x0E,0x00,0x0E,0x00,0x1F,0x00, // p
0x00,0x00,0x00,0x00,0x00,0x00,0x00,0x00,0x00,0x00,0x00,0x00,0x1F,0xB0,0x38,0xE0,0x38,0xE0,0x38,0xE0,0x38,0xE0,0x38,0xE0,0x1F,0xE0,0x00,0xE0,0x00,0xE0,0x01,0xF0, // q
0x00,0x00,0x00,0x00,0x00,0x00,0x00,0x00,0x00,0x00,0x00,0x00,0x1E,0xF0,0x0F,0xF8,0x0F,0x38,0x0E,0x00,0x0E,0x00,0x0E,0x00,0x0E,0x00,0x1F,0x00,0x00,0x00,0x00,0x00, // r
0x00,0x00,0x00,0x00,0x00,0x00,0x00,0x00,0x00,0x00,0x00,0x00,0x0F,0xE0,0x1C,0x30,0x1C,0x30,0x0F,0x80,0x03,0xE0,0x18,0x70,0x18,0x70,0x0F,0xE0,0x00,0x00,0x00,0x00, // s
0x00,0x00,0x00,0x00,0x00,0x00,0x01,0x00,0x03,0x00,0x07,0x00,0x1F,0xF0,0x07,0x00,0x07,0x00,0x07,0x00,0x07,0x00,0x07,0x70,0x07,0x70,0x03,0xE0,0x00,0x00,0x00,0x00, // t
0x00,0x00,0x00,0x00,0x00,0x00,0x00,0x00,0x00,0x00,0x00,0x00,0x1C,0x70,0x1C,0x70,0x1C,0x70,0x1C,0x70,0x1C,0x70,0x1C,0x70,0x1C,0x70,0x0F,0xD8,0x00,0x00,0x00,0x00, // u
0x00,0x00,0x00,0x00,0x00,0x00,0x00,0x00,0x00,0x00,0x00,0x00,0x1C,0x70,0x1C,0x70,0x1C,0x70,0x1C,0x70,0x1C,0x70,0x0E,0xE0,0x07,0xC0,0x03,0x80,0x00,0x00,0x00,0x00, // v
0x00,0x00,0x00,0x00,0x00,0x00,0x00,0x00,0x00,0x00,0x00,0x00,0x1C,0x1C,0x1C,0x1C,0x1C,0x1C,0x1C,0x9C,0x1C,0x9C,0x0F,0xF8,0x07,0x70,0x07,0x70,0x00,0x00,0x00,0x00, // w
0x00,0x00,0x00,0x00,0x00,0x00,0x00,0x00,0x00,0x00,0x00,0x00,0x1C,0xE0,0x1C,0xE0,0x0F,0xC0,0x07,0x80,0x07,0x80,0x0F,0xC0,0x1C,0xE0,0x1C,0xE0,0x00,0x00,0x00,0x00, // x
0x00,0x00,0x00,0x00,0x00,0x00,0x00,0x00,0x00,0x00,0x00,0x00,0x0E,0x38,0x0E,0x38,0x0E,0x38,0x0E,0x38,0x0E,0x38,0x07,0xF0,0x03,0xE0,0x00,0xE0,0x01,0xC0,0x1F,0x80, // y
0x00,0x00,0x00,0x00,0x00,0x00,0x00,0x00,0x00,0x00,0x00,0x00,0x1F,0xE0,0x18,0xE0,0x11,0xC0,0x03,0x80,0x07,0x00,0x0E,0x20,0x1C,0x60,0x1F,0xE0,0x00,0x00,0x00,0x00, // z
0x00,0x00,0x00,0x00,0x01,0xF8,0x03,0x80,0x03,0x80,0x03,0x80,0x07,0x00,0x1C,0x00,0x1C,0x00,0x07,0x00,0x03,0x80,0x03,0x80,0x03,0x80,0x01,0xF8,0x00,0x00,0x00,0x00, // {
0x00,0x00,0x01,0xC0,0x01,0xC0,0x01,0xC0,0x01,0xC0,0x01,0xC0,0x01,0xC0,0x01,0xC0,0x01,0xC0,0x01,0xC0,0x01,0xC0,0x01,0xC0,0x01,0xC0,0x01,0xC0,0x01,0xC0,0x00,0x00, // |
0x00,0x00,0x00,0x00,0x1F,0x80,0x01,0xC0,0x01,0xC0,0x01,0xC0,0x00,0xE0,0x00,0x38,0x00,0x38,0x00,0xE0,0x01,0xC0,0x01,0xC0,0x01,0xC0,0x1F,0x80,0x00,0x00,0x00,0x00, // }
0x00,0x00,0x00,0x00,0x1F,0x1C,0x3B,0x9C,0x39,0xDC,0x38,0xF8,0x00,0x00,0x00,0x00,0x00,0x00,0x00,0x00,0x00,0x00,0x00,0x00,0x00,0x00,0x00,0x00,0x00,0x00,0x00,0x00, // ~
0x00,0x00,0x00,0x00,0x00,0xF0,0x01,0xF8,0x01,0x98,0x01,0x98,0x01,0xF8,0x00,0xF0,0x00,0x00,0x00,0x00,0x00,0x00,0x00,0x00,0x00,0x00,0x00,0x00,0x00,0x00,0x00,0x00, // градус
0x00,0x00,0x00,0x00,0x1F,0xF8,0x0E,0x18,0x0E,0x08,0x0E,0x00,0x0E,0x00,0x0F,0xF0,0x0E,0x38,0x0E,0x38,0x0E,0x38,0x0E,0x38,0x0E,0x38,0x1F,0xF0,0x00,0x00,0x00,0x00, // Б
0x00,0x00,0x00,0x00,0x1F,0xF8,0x0E,0x18,0x0E,0x08,0x0E,0x00,0x0E,0x00,0x0E,0x00,0x0E,0x00,0x0E,0x00,0x0E,0x00,0x0E,0x00,0x0E,0x00,0x1F,0x00,0x00,0x00,0x00,0x00, // Г
0x00,0x00,0x00,0x00,0x07,0xF0,0x0C,0x70,0x1C,0x70,0x1C,0x70,0x1C,0x70,0x1C,0x70,0x1C,0x70,0x1C,0x70,0x1C,0x70,0x1C,0x70,0x1C,0x70,0x3F,0xF8,0x30,0x18,0x20,0x08, // Д
0x06,0x60,0x00,0x00,0x1F,0xF8,0x0E,0x18,0x0E,0x08,0x0E,0x00,0x0E,0x30,0x0F,0xF0,0x0F,0xF0,0x0E,0x30,0x0E,0x00,0x0E,0x08,0x0E,0x18,0x1F,0xF8,0x00,0x00,0x00,0x00, // Ё
0x00,0x00,0x00,0x00,0x33,0xCC,0x19,0x98,0x19,0x98,0x19,0x98,0x0D,0xB0,0x0F,0xF0,0x0F,0xF0,0x1D,0xB8,0x19,0x98,0x19,0x98,0x19,0x98,0x33,0xCC,0x00,0x00,0x00,0x00, // Ж
0x00,0x00,0x00,0x00,0x17,0xE0,0x1E,0x70,0x1C,0x38,0x10,0x38,0x00,0x70,0x03,0xC0,0x03,0xC0,0x00,0x70,0x00,0x38,0x1C,0x38,0x1C,0x70,0x0F,0xE0,0x00,0x00,0x00,0x00, // З
0x00,0x00,0x00,0x00,0x1C,0x70,0x1C,0x70,0x1C,0x70,0x1C,0x70,0x1C,0x70,0x1C,0x70,0x1C,0xF0,0x1D,0xF0,0x1F,0x70,0x1E,0x70,0x1C,0x70,0x1C,0x70,0x00,0x00,0x00,0x00, // �?
0x03,0x80,0x00,0x00,0x1C,0x70,0x1C,0x70,0x1C,0x70,0x1C,0x70,0x1C,0x70,0x1C,0x70,0x1C,0xF0,0x1D,0xF0,0x1F,0x70,0x1E,0x70,0x1C,0x70,0x1C,0x70,0x00,0x00,0x00,0x00, // Й
0x00,0x00,0x00,0x00,0x03,0xF0,0x06,0x70,0x0E,0x70,0x0E,0x70,0x0E,0x70,0x0E,0x70,0x0E,0x70,0x0E,0x70,0x0E,0x70,0x0E,0x70,0x0E,0x70,0x1C,0x70,0x00,0x00,0x00,0x00, // Л
0x00,0x00,0x00,0x00,0x1F,0xF0,0x1C,0x70,0x1C,0x70,0x1C,0x70,0x1C,0x70,0x1C,0x70,0x1C,0x70,0x1C,0x70,0x1C,0x70,0x1C,0x70,0x1C,0x70,0x1C,0x70,0x00,0x00,0x00,0x00, // П
0x00,0x00,0x00,0x00,0x1C,0x70,0x1C,0x70,0x1C,0x70,0x1C,0x70,0x1C,0x70,0x1C,0x70,0x0F,0xF0,0x07,0xF0,0x00,0x70,0x00,0x70,0x1C,0xE0,0x0F,0xC0,0x00,0x00,0x00,0x00, // У
0x00,0x00,0x00,0x00,0x1F,0xF0,0x33,0x98,0x33,0x98,0x33,0x98,0x33,0x98,0x33,0x98,0x33,0x98,0x33,0x98,0x1F,0xF0,0x03,0x80,0x03,0x80,0x07,0xC0,0x00,0x00,0x00,0x00, // Ф
0x00,0x00,0x00,0x00,0x1C,0x70,0x1C,0x70,0x1C,0x70,0x1C,0x70,0x1C,0x70,0x1C,0x70,0x1C,0x70,0x1C,0x70,0x1C,0x70,0x1C,0x70,0x1C,0x70,0x1F,0xF8,0x00,0x18,0x00,0x08, // Ц
0x00,0x00,0x00,0x00,0x1C,0x70,0x1C,0x70,0x1C,0x70,0x1C,0x70,0x1C,0x70,0x1C,0x70,0x1F,0xF0,0x0F,0xF0,0x00,0x70,0x00,0x70,0x00,0x70,0x00,0x70,0x00,0x00,0x00,0x00, // Ч
0x00,0x00,0x00,0x00,0x39,0x9C,0x39,0x9C,0x39,0x9C,0x39,0x9C,0x39,0x9C,0x39,0x9C,0x39,0x9C,0x39,0x9C,0x39,0x9C,0x39,0x9C,0x39,0x9C,0x3F,0xFC,0x00,0x00,0x00,0x00, // Ш
0x00,0x00,0x00,0x00,0x39,0x9C,0x39,0x9C,0x39,0x9C,0x39,0x9C,0x39,0x9C,0x39,0x9C,0x39,0x9C,0x39,0x9C,0x39,0x9C,0x39,0x9C,0x39,0x9C,0x3F,0xFE,0x00,0x06,0x00,0x02, // Щ
0x00,0x00,0x00,0x00,0x3F,0x00,0x2E,0x00,0x2E,0x00,0x0E,0x00,0x0E,0x00,0x0F,0xF0,0x0E,0x38,0x0E,0x38,0x0E,0x38,0x0E,0x38,0x0E,0x38,0x1F,0xF0,0x00,0x00,0x00,0x00, // Ъ
0x00,0x00,0x00,0x00,0x38,0x1C,0x38,0x1C,0x38,0x1C,0x38,0x1C,0x38,0x1C,0x3F,0x9C,0x39,0xDC,0x39,0xDC,0x39,0xDC,0x39,0xDC,0x39,0xDC,0x3F,0x9C,0x00,0x00,0x00,0x00, // Ы
0x00,0x00,0x00,0x00,0x1F,0x00,0x0E,0x00,0x0E,0x00,0x0E,0x00,0x0E,0x00,0x0F,0xF0,0x0E,0x38,0x0E,0x38,0x0E,0x38,0x0E,0x38,0x0E,0x38,0x1F,0xF0,0x00,0x00,0x00,0x00, // Ь
0x00,0x00,0x00,0x00,0x0F,0xE0,0x1C,0x70,0x1C,0x38,0x00,0x38,0x00,0x38,0x03,0xF8,0x03,0xF8,0x00,0x38,0x00,0x38,0x1C,0x38,0x1C,0x70,0x0F,0xE0,0x00,0x00,0x00,0x00, // Э
0x00,0x00,0x00,0x00,0x3C,0xF8,0x1D,0x9C,0x1D,0x9C,0x1D,0x9C,0x1D,0x9C,0x1F,0x9C,0x1F,0x9C,0x1D,0x9C,0x1D,0x9C,0x1D,0x9C,0x1D,0x9C,0x3C,0xF8,0x00,0x00,0x00,0x00, // Ю
0x00,0x00,0x00,0x00,0x0F,0xF8,0x1C,0x70,0x1C,0x70,0x1C,0x70,0x1C,0x70,0x1C,0x70,0x1F,0xF0,0x0F,0xF0,0x1C,0x70,0x1C,0x70,0x1C,0x70,0x38,0x78,0x00,0x00,0x00,0x00, // Я
0x00,0x00,0x00,0x00,0x00,0x18,0x07,0xF8,0x0F,0x00,0x0E,0x00,0x0E,0x00,0x0F,0xF0,0x0E,0x38,0x0E,0x38,0x0E,0x38,0x0E,0x38,0x0E,0x38,0x07,0xF0,0x00,0x00,0x00,0x00, // б
0x00,0x00,0x00,0x00,0x00,0x00,0x00,0x00,0x00,0x00,0x00,0x00,0x1F,0xF0,0x0E,0x38,0x0E,0x38,0x0F,0xF0,0x0E,0x38,0x0E,0x38,0x0E,0x38,0x1F,0xF0,0x00,0x00,0x00,0x00, // в
0x00,0x00,0x00,0x00,0x00,0x00,0x00,0x00,0x00,0x00,0x00,0x00,0x1F,0xF8,0x1C,0x38,0x1C,0x00,0x1C,0x00,0x1C,0x00,0x1C,0x00,0x1C,0x00,0x1C,0x00,0x00,0x00,0x00,0x00, // г
0x00,0x00,0x00,0x00,0x00,0x00,0x00,0x00,0x00,0x00,0x00,0x00,0x07,0xF0,0x0E,0x70,0x0E,0x70,0x0E,0x70,0x0E,0x70,0x0E,0x70,0x0E,0x70,0x1F,0xF8,0x10,0x08,0x00,0x00, // д
0x00,0x00,0x00,0x00,0x00,0x00,0x00,0x00,0x06,0xC0,0x00,0x00,0x0F,0xE0,0x1C,0x70,0x1C,0x70,0x1F,0xF0,0x1C,0x00,0x1C,0x70,0x1C,0x70,0x0F,0xE0,0x00,0x00,0x00,0x00, // ё
0x00,0x00,0x00,0x00,0x00,0x00,0x00,0x00,0x00,0x00,0x00,0x00,0x19,0xCC,0x19,0xCC,0x19,0xCC,0x0D,0xD8,0x07,0xF0,0x0D,0xD8,0x19,0xCC,0x19,0xCC,0x00,0x00,0x00,0x00, // ж
0x00,0x00,0x00,0x00,0x00,0x00,0x00,0x00,0x00,0x00,0x00,0x00,0x0F,0xE0,0x1C,0x70,0x00,0x70,0x03,0xE0,0x00,0x70,0x00,0x70,0x1C,0x70,0x0F,0xE0,0x00,0x00,0x00,0x00, // з
0x00,0x00,0x00,0x00,0x00,0x00,0x00,0x00,0x00,0x00,0x00,0x00,0x1C,0x70,0x1C,0x70,0x1C,0x70,0x1C,0xF0,0x1D,0x70,0x1E,0x70,0x1C,0x70,0x1C,0x70,0x00,0x00,0x00,0x00, // и
0x00,0x00,0x00,0x00,0x00,0x00,0x00,0x00,0x01,0xC0,0x00,0x00,0x0E,0x38,0x0E,0x38,0x0E,0x38,0x0E,0x78,0x0E,0xB8,0x0F,0x38,0x0E,0x38,0x0E,0x38,0x00,0x00,0x00,0x00, // й
0x00,0x00,0x00,0x00,0x00,0x00,0x00,0x00,0x00,0x00,0x00,0x00,0x0E,0x38,0x0E,0x38,0x0E,0x70,0x0F,0xE0,0x0E,0x70,0x0E,0x38,0x0E,0x38,0x0E,0x38,0x00,0x00,0x00,0x00, // к
0x00,0x00,0x00,0x00,0x00,0x00,0x00,0x00,0x00,0x00,0x00,0x00,0x03,0xF8,0x07,0x38,0x07,0x38,0x07,0x38,0x07,0x38,0x07,0x38,0x07,0x38,0x0E,0x38,0x00,0x00,0x00,0x00, // л
0x00,0x00,0x00,0x00,0x00,0x00,0x00,0x00,0x00,0x00,0x00,0x00,0x38,0x38,0x38,0x38,0x38,0x38,0x3C,0x78,0x3A,0xB8,0x39,0x38,0x38,0x38,0x38,0x38,0x00,0x00,0x00,0x00, // м
0x00,0x00,0x00,0x00,0x00,0x00,0x00,0x00,0x00,0x00,0x00,0x00,0x1C,0x70,0x1C,0x70,0x1C,0x70,0x1C,0x70,0x1F,0xF0,0x1C,0x70,0x1C,0x70,0x1C,0x70,0x00,0x00,0x00,0x00, // н
0x00,0x00,0x00,0x00,0x00,0x00,0x00,0x00,0x00,0x00,0x00,0x00,0x1F,0xF0,0x1C,0x70,0x1C,0x70,0x1C,0x70,0x1C,0x70,0x1C,0x70,0x1C,0x70,0x1C,0x70,0x00,0x00,0x00,0x00, // п
0x00,0x00,0x00,0x00,0x00,0x00,0x00,0x00,0x00,0x00,0x00,0x00,0x1F,0xF0,0x13,0x90,0x03,0x80,0x03,0x80,0x03,0x80,0x03,0x80,0x03,0x80,0x03,0x80,0x00,0x00,0x00,0x00, // т
0x00,0x00,0x00,0x00,0x00,0x00,0x00,0x00,0x00,0x00,0x03,0x80,0x1F,0xF0,0x3B,0xB8,0x3B,0xB8,0x3B,0xB8,0x3B,0xB8,0x0F,0xF0,0x03,0x80,0x03,0x80,0x03,0x80,0x00,0x00, // ф
0x00,0x00,0x00,0x00,0x00,0x00,0x00,0x00,0x00,0x00,0x00,0x00,0x1C,0x70,0x1C,0x70,0x1C,0x70,0x1C,0x70,0x1C,0x70,0x1C,0x70,0x1C,0x70,0x1F,0xF8,0x00,0x18,0x00,0x00, // ц
0x00,0x00,0x00,0x00,0x00,0x00,0x00,0x00,0x00,0x00,0x00,0x00,0x1C,0x70,0x1C,0x70,0x1C,0x70,0x1C,0x70,0x0F,0xF0,0x00,0x70,0x00,0x70,0x00,0x70,0x00,0x00,0x00,0x00, // ч
0x00,0x00,0x00,0x00,0x00,0x00,0x00,0x00,0x00,0x00,0x00,0x00,0x39,0x9C,0x39,0x9C,0x39,0x9C,0x39,0x9C,0x39,0x9C,0x39,0x9C,0x39,0x9C,0x3F,0xFC,0x00,0x00,0x00,0x00, // ш
0x00,0x00,0x00,0x00,0x00,0x00,0x00,0x00,0x00,0x00,0x00,0x00,0x39,0x9C,0x39,0x9C,0x39,0x9C,0x39,0x9C,0x39,0x9C,0x39,0x9C,0x39,0x9C,0x3F,0xFE,0x00,0x06,0x00,0x00, // щ
0x00,0x00,0x00,0x00,0x00,0x00,0x00,0x00,0x00,0x00,0x00,0x00,0x3E,0x00,0x2E,0x00,0x0E,0x00,0x0F,0xF0,0x0E,0x38,0x0E,0x38,0x0E,0x38,0x0F,0xF0,0x00,0x00,0x00,0x00, // ъ
0x00,0x00,0x00,0x00,0x00,0x00,0x00,0x00,0x00,0x00,0x00,0x00,0x38,0x1C,0x38,0x1C,0x38,0x1C,0x3F,0x9C,0x39,0xDC,0x39,0xDC,0x39,0xDC,0x3F,0x9C,0x00,0x00,0x00,0x00, // ы
0x00,0x00,0x00,0x00,0x00,0x00,0x00,0x00,0x00,0x00,0x00,0x00,0x0E,0x00,0x0E,0x00,0x0E,0x00,0x0F,0xF0,0x0E,0x38,0x0E,0x38,0x0E,0x38,0x0F,0xF0,0x00,0x00,0x00,0x00, // ь
0x00,0x00,0x00,0x00,0x00,0x00,0x00,0x00,0x00,0x00,0x00,0x00,0x0F,0xE0,0x1C,0x70,0x00,0x70,0x03,0xF0,0x00,0x70,0x00,0x70,0x1C,0x70,0x0F,0xE0,0x00,0x00,0x00,0x00, // э
0x00,0x00,0x00,0x00,0x00,0x00,0x00,0x00,0x00,0x00,0x00,0x00,0x38,0xF8,0x39,0x9C,0x39,0x9C,0x39,0x9C,0x3F,0x9C,0x39,0x9C,0x39,0x9C,0x38,0xF8,0x00,0x00,0x00,0x00, // ю
0x00,0x00,0x00,0x00,0x00,0x00,0x00,0x00,0x00,0x00,0x00,0x00,0x07,0xF8,0x0E,0x38,0x0E,0x38,0x0E,0x38,0x07,0xF8,0x0E,0x38,0x0E,0x38,0x1C,0x38,0x00,0x00,0x00,0x00, // я
};

// SevenSegNumFont.c
// Font Size	: 32x50
// Memory usage	: 2004 bytes
// # characters	: 10
const uint8_t SevenSegNumFont[2004] ={
0x20,0x32,0x30,0x0A,
0x00,0x00,0x00,0x00,0x00,0x00,0x00,0x00,0x00,0xFF,0xFE,0x00,0x01,0xFF,0xFF,0x00,0x03,0xFF,0xFF,0x80,0x01,0xFF,0xFF,0x60,0x0C,0xFF,0xFE,0xF0,0x1E,0x00,0x01,0xF8,0x3F,0x00,0x01,0xF8,0x3F,0x00,0x01,0xF8,0x3F,0x00,0x01,0xF8,0x3F,0x00,0x01,0xF8,0x3F,0x00,0x01,0xF8,0x3F,0x00,0x01,0xF8,0x3F,0x00,0x01,0xF8,0x3F,0x00,0x01,0xF8,0x3F,0x00,0x01,0xF8,0x3F,0x00,0x01,0xF8,0x3F,0x00,0x01,0xF8,0x3F,0x00,0x01,0xF8,0x3F,0x00,0x01,0xF8,0x3E,0x00,0x00,0x78,0x38,0x00,0x00,0x18,0x20,0x00,0x00,0x08,0x00,0x00,0x00,0x00,0x20,0x00,0x00,0x00,0x38,0x00,0x00,0x18,0x3E,0x00,0x00,0x78,0x3F,0x00,0x01,0xF8,0x3F,0x00,0x01,0xF8,0x3F,0x00,0x01,0xF8,0x3F,0x00,0x01,0xF8,0x3F,0x00,0x01,0xF8,0x3F,0x00,0x01,0xF8,0x3F,0x00,0x01,0xF8,0x3F,0x00,0x01,0xF8,0x3F,0x00,0x01,0xF8,0x3F,0x00,0x01,0xF8,0x3F,0x00,0x01,0xF8,0x3F,0x00,0x01,0xF8,0x3F,0x00,0x01,0xF8,0x3F,0x00,0x01,0xF8,0x1E,0x00,0x00,0xF0,0x0C,0xFF,0xFE,0x60,0x01,0xFF,0xFF,0x00,0x03,0xFF,0xFF,0x80,0x01,0xFF,0xFF,0x00,0x00,0xFF,0xFE,0x00,0x00,0x00,0x00,0x00,0x00,0x00,0x00,0x00,  // 0
0x00,0x00,0x00,0x00,0x00,0x00,0x00,0x00,0x00,0x00,0x00,0x00,0x00,0x00,0x00,0x00,0x00,0x00,0x00,0x00,0x00,0x00,0x00,0x60,0x00,0x00,0x00,0xF0,0x00,0x00,0x01,0xF8,0x00,0x00,0x01,0xF8,0x00,0x00,0x01,0xF8,0x00,0x00,0x01,0xF8,0x00,0x00,0x01,0xF8,0x00,0x00,0x01,0xF8,0x00,0x00,0x01,0xF8,0x00,0x00,0x01,0xF8,0x00,0x00,0x01,0xF8,0x00,0x00,0x01,0xF8,0x00,0x00,0x01,0xF8,0x00,0x00,0x01,0xF8,0x00,0x00,0x01,0xF8,0x00,0x00,0x01,0xF8,0x00,0x00,0x00,0x78,0x00,0x00,0x00,0x18,0x00,0x00,0x00,0x08,0x00,0x00,0x00,0x00,0x00,0x00,0x00,0x00,0x00,0x00,0x00,0x18,0x00,0x00,0x00,0x78,0x00,0x00,0x01,0xF8,0x00,0x00,0x01,0xF8,0x00,0x00,0x01,0xF8,0x00,0x00,0x01,0xF8,0x00,0x00,0x01,0xF8,0x00,0x00,0x01,0xF8,0x00,0x00,0x01,0xF8,0x00,0x00,0x01,0xF8,0x00,0x00,0x01,0xF8,0x00,0x00,0x01,0xF8,0x00,0x00,0x01,0xF8,0x00,0x00,0x01,0xF8,0x00,0x00,0x01,0xF8,0x00,0x00,0x01,0xF8,0x00,0x00,0x00,0xF0,0x00,0x00,0x00,0x60,0x00,0x00,0x00,0x00,0x00,0x00,0x00,0x00,0x00,0x00,0x00,0x00,0x00,0x00,0x00,0x00,0x00,0x00,0x00,0x00,0x00,0x00,0x00,0x00,  // 1
0x00,0x00,0x00,0x00,0x00,0x00,0x00,0x00,0x00,0xFF,0xFE,0x00,0x01,0xFF,0xFF,0x00,0x03,0xFF,0xFF,0x80,0x01,0xFF,0xFF,0x60,0x00,0xFF,0xFE,0xF0,0x00,0x00,0x01,0xF8,0x00,0x00,0x01,0xF8,0x00,0x00,0x01,0xF8,0x00,0x00,0x01,0xF8,0x00,0x00,0x01,0xF8,0x00,0x00,0x01,0xF8,0x00,0x00,0x01,0xF8,0x00,0x00,0x01,0xF8,0x00,0x00,0x01,0xF8,0x00,0x00,0x01,0xF8,0x00,0x00,0x01,0xF8,0x00,0x00,0x01,0xF8,0x00,0x00,0x01,0xF8,0x00,0x00,0x01,0xF8,0x00,0x00,0x00,0x78,0x01,0xFF,0xFE,0x18,0x03,0xFF,0xFF,0x88,0x0F,0xFF,0xFF,0xE0,0x27,0xFF,0xFF,0xC0,0x39,0xFF,0xFF,0x00,0x3E,0x00,0x00,0x00,0x3F,0x00,0x00,0x00,0x3F,0x00,0x00,0x00,0x3F,0x00,0x00,0x00,0x3F,0x00,0x00,0x00,0x3F,0x00,0x00,0x00,0x3F,0x00,0x00,0x00,0x3F,0x00,0x00,0x00,0x3F,0x00,0x00,0x00,0x3F,0x00,0x00,0x00,0x3F,0x00,0x00,0x00,0x3F,0x00,0x00,0x00,0x3F,0x00,0x00,0x00,0x3F,0x00,0x00,0x00,0x3F,0x00,0x00,0x00,0x1E,0x00,0x00,0x00,0x0C,0xFF,0xFE,0x00,0x01,0xFF,0xFF,0x00,0x03,0xFF,0xFF,0x80,0x01,0xFF,0xFF,0x00,0x00,0xFF,0xFE,0x00,0x00,0x00,0x00,0x00,0x00,0x00,0x00,0x00,  // 2
0x00,0x00,0x00,0x00,0x00,0x00,0x00,0x00,0x00,0xFF,0xFE,0x00,0x01,0xFF,0xFF,0x00,0x03,0xFF,0xFF,0x80,0x01,0xFF,0xFF,0x60,0x00,0xFF,0xFE,0xF0,0x00,0x00,0x01,0xF8,0x00,0x00,0x01,0xF8,0x00,0x00,0x01,0xF8,0x00,0x00,0x01,0xF8,0x00,0x00,0x01,0xF8,0x00,0x00,0x01,0xF8,0x00,0x00,0x01,0xF8,0x00,0x00,0x01,0xF8,0x00,0x00,0x01,0xF8,0x00,0x00,0x01,0xF8,0x00,0x00,0x01,0xF8,0x00,0x00,0x01,0xF8,0x00,0x00,0x01,0xF8,0x00,0x00,0x01,0xF8,0x00,0x00,0x00,0x78,0x01,0xFF,0xFE,0x18,0x03,0xFF,0xFF,0x88,0x0F,0xFF,0xFF,0xE0,0x07,0xFF,0xFF,0xC0,0x01,0xFF,0xFF,0x18,0x00,0x00,0x00,0x78,0x00,0x00,0x01,0xF8,0x00,0x00,0x01,0xF8,0x00,0x00,0x01,0xF8,0x00,0x00,0x01,0xF8,0x00,0x00,0x01,0xF8,0x00,0x00,0x01,0xF8,0x00,0x00,0x01,0xF8,0x00,0x00,0x01,0xF8,0x00,0x00,0x01,0xF8,0x00,0x00,0x01,0xF8,0x00,0x00,0x01,0xF8,0x00,0x00,0x01,0xF8,0x00,0x00,0x01,0xF8,0x00,0x00,0x01,0xF8,0x00,0x00,0x00,0xF0,0x00,0xFF,0xFE,0x60,0x01,0xFF,0xFF,0x00,0x03,0xFF,0xFF,0x80,0x01,0xFF,0xFF,0x00,0x00,0xFF,0xFE,0x00,0x00,0x00,0x00,0x00,0x00,0x00,0x00,0x00,  // 3
0x00,0x00,0x00,0x00,0x00,0x00,0x00,0x00,0x00,0x00,0x00,0x00,0x00,0x00,0x00,0x00,0x00,0x00,0x00,0x00,0x00,0x00,0x00,0x60,0x0C,0x00,0x00,0xF0,0x1E,0x00,0x01,0xF8,0x3F,0x00,0x01,0xF8,0x3F,0x00,0x01,0xF8,0x3F,0x00,0x01,0xF8,0x3F,0x00,0x01,0xF8,0x3F,0x00,0x01,0xF8,0x3F,0x00,0x01,0xF8,0x3F,0x00,0x01,0xF8,0x3F,0x00,0x01,0xF8,0x3F,0x00,0x01,0xF8,0x3F,0x00,0x01,0xF8,0x3F,0x00,0x01,0xF8,0x3F,0x00,0x01,0xF8,0x3F,0x00,0x01,0xF8,0x3E,0x00,0x00,0x78,0x39,0xFF,0xFE,0x18,0x23,0xFF,0xFF,0x88,0x0F,0xFF,0xFF,0xE0,0x07,0xFF,0xFF,0xC0,0x01,0xFF,0xFF,0x18,0x00,0x00,0x00,0x78,0x00,0x00,0x01,0xF8,0x00,0x00,0x01,0xF8,0x00,0x00,0x01,0xF8,0x00,0x00,0x01,0xF8,0x00,0x00,0x01,0xF8,0x00,0x00,0x01,0xF8,0x00,0x00,0x01,0xF8,0x00,0x00,0x01,0xF8,0x00,0x00,0x01,0xF8,0x00,0x00,0x01,0xF8,0x00,0x00,0x01,0xF8,0x00,0x00,0x01,0xF8,0x00,0x00,0x01,0xF8,0x00,0x00,0x01,0xF8,0x00,0x00,0x00,0xF0,0x00,0x00,0x00,0x60,0x00,0x00,0x00,0x00,0x00,0x00,0x00,0x00,0x00,0x00,0x00,0x00,0x00,0x00,0x00,0x00,0x00,0x00,0x00,0x00,0x00,0x00,0x00,0x00,  // 4
0x00,0x00,0x00,0x00,0x00,0x00,0x00,0x00,0x00,0xFF,0xFE,0x00,0x01,0xFF,0xFF,0x00,0x03,0xFF,0xFF,0x80,0x01,0xFF,0xFF,0x00,0x0C,0xFF,0xFE,0x00,0x1E,0x00,0x00,0x00,0x3F,0x00,0x00,0x00,0x3F,0x00,0x00,0x00,0x3F,0x00,0x00,0x00,0x3F,0x00,0x00,0x00,0x3F,0x00,0x00,0x00,0x3F,0x00,0x00,0x00,0x3F,0x00,0x00,0x00,0x3F,0x00,0x00,0x00,0x3F,0x00,0x00,0x00,0x3F,0x00,0x00,0x00,0x3F,0x00,0x00,0x00,0x3F,0x00,0x00,0x00,0x3F,0x00,0x00,0x00,0x3E,0x00,0x00,0x00,0x39,0xFF,0xFE,0x00,0x23,0xFF,0xFF,0x80,0x0F,0xFF,0xFF,0xE0,0x07,0xFF,0xFF,0xC0,0x01,0xFF,0xFF,0x18,0x00,0x00,0x00,0x78,0x00,0x00,0x01,0xF8,0x00,0x00,0x01,0xF8,0x00,0x00,0x01,0xF8,0x00,0x00,0x01,0xF8,0x00,0x00,0x01,0xF8,0x00,0x00,0x01,0xF8,0x00,0x00,0x01,0xF8,0x00,0x00,0x01,0xF8,0x00,0x00,0x01,0xF8,0x00,0x00,0x01,0xF8,0x00,0x00,0x01,0xF8,0x00,0x00,0x01,0xF8,0x00,0x00,0x01,0xF8,0x00,0x00,0x01,0xF8,0x00,0x00,0x00,0xF0,0x00,0xFF,0xFE,0x60,0x01,0xFF,0xFF,0x00,0x03,0xFF,0xFF,0x80,0x01,0xFF,0xFF,0x00,0x00,0xFF,0xFE,0x00,0x00,0x00,0x00,0x00,0x00,0x00,0x00,0x00,  // 5
0x00,0x00,0x00,0x00,0x00,0x00,0x00,0x00,0x00,0xFF,0xFE,0x00,0x01,0xFF,0xFF,0x00,0x03,0xFF,0xFF,0x80,0x01,0xFF,0xFF,0x00,0x0C,0xFF,0xFE,0x00,0x1E,0x00,0x00,0x00,0x3F,0x00,0x00,0x00,0x3F,0x00,0x00,0x00,0x3F,0x00,0x00,0x00,0x3F,0x00,0x00,0x00,0x3F,0x00,0x00,0x00,0x3F,0x00,0x00,0x00,0x3F,0x00,0x00,0x00,0x3F,0x00,0x00,0x00,0x3F,0x00,0x00,0x00,0x3F,0x00,0x00,0x00,0x3F,0x00,0x00,0x00,0x3F,0x00,0x00,0x00,0x3F,0x00,0x00,0x00,0x3E,0x00,0x00,0x00,0x39,0xFF,0xFE,0x00,0x23,0xFF,0xFF,0x80,0x0F,0xFF,0xFF,0xE0,0x27,0xFF,0xFF,0xC0,0x39,0xFF,0xFF,0x18,0x3E,0x00,0x00,0x78,0x3F,0x00,0x01,0xF8,0x3F,0x00,0x01,0xF8,0x3F,0x00,0x01,0xF8,0x3F,0x00,0x01,0xF8,0x3F,0x00,0x01,0xF8,0x3F,0x00,0x01,0xF8,0x3F,0x00,0x01,0xF8,0x3F,0x00,0x01,0xF8,0x3F,0x00,0x01,0xF8,0x3F,0x00,0x01,0xF8,0x3F,0x00,0x01,0xF8,0x3F,0x00,0x01,0xF8,0x3F,0x00,0x01,0xF8,0x3F,0x00,0x01,0xF8,0x1E,0x00,0x00,0xF0,0x0C,0xFF,0xFE,0x60,0x01,0xFF,0xFF,0x00,0x03,0xFF,0xFF,0x80,0x01,0xFF,0xFF,0x00,0x00,0xFF,0xFE,0x00,0x00,0x00,0x00,0x00,0x00,0x00,0x00,0x00,  // 6
0x00,0x00,0x00,0x00,0x00,0x00,0x00,0x00,0x00,0xFF,0xFE,0x00,0x01,0xFF,0xFF,0x00,0x03,0xFF,0xFF,0x80,0x01,0xFF,0xFF,0x60,0x00,0xFF,0xFE,0xF0,0x00,0x00,0x01,0xF8,0x00,0x00,0x01,0xF8,0x00,0x00,0x01,0xF8,0x00,0x00,0x01,0xF8,0x00,0x00,0x01,0xF8,0x00,0x00,0x01,0xF8,0x00,0x00,0x01,0xF8,0x00,0x00,0x01,0xF8,0x00,0x00,0x01,0xF8,0x00,0x00,0x01,0xF8,0x00,0x00,0x01,0xF8,0x00,0x00,0x01,0xF8,0x00,0x00,0x01,0xF8,0x00,0x00,0x01,0xF8,0x00,0x00,0x00,0x78,0x00,0x00,0x00,0x18,0x00,0x00,0x00,0x08,0x00,0x00,0x00,0x00,0x00,0x00,0x00,0x00,0x00,0x00,0x00,0x18,0x00,0x00,0x00,0x78,0x00,0x00,0x01,0xF8,0x00,0x00,0x01,0xF8,0x00,0x00,0x01,0xF8,0x00,0x00,0x01,0xF8,0x00,0x00,0x01,0xF8,0x00,0x00,0x01,0xF8,0x00,0x00,0x01,0xF8,0x00,0x00,0x01,0xF8,0x00,0x00,0x01,0xF8,0x00,0x00,0x01,0xF8,0x00,0x00,0x01,0xF8,0x00,0x00,0x01,0xF8,0x00,0x00,0x01,0xF8,0x00,0x00,0x01,0xF8,0x00,0x00,0x00,0xF0,0x00,0x00,0x00,0x60,0x00,0x00,0x00,0x00,0x00,0x00,0x00,0x00,0x00,0x00,0x00,0x00,0x00,0x00,0x00,0x00,0x00,0x00,0x00,0x00,0x00,0x00,0x00,0x00,  // 7
0x00,0x00,0x00,0x00,0x00,0x00,0x00,0x00,0x00,0xFF,0xFE,0x00,0x01,0xFF,0xFF,0x00,0x03,0xFF,0xFF,0x80,0x01,0xFF,0xFF,0x60,0x0C,0xFF,0xFE,0xF0,0x1E,0x00,0x01,0xF8,0x3F,0x00,0x01,0xF8,0x3F,0x00,0x01,0xF8,0x3F,0x00,0x01,0xF8,0x3F,0x00,0x01,0xF8,0x3F,0x00,0x01,0xF8,0x3F,0x00,0x01,0xF8,0x3F,0x00,0x01,0xF8,0x3F,0x00,0x01,0xF8,0x3F,0x00,0x01,0xF8,0x3F,0x00,0x01,0xF8,0x3F,0x00,0x01,0xF8,0x3F,0x00,0x01,0xF8,0x3F,0x00,0x01,0xF8,0x3E,0x00,0x00,0x78,0x39,0xFF,0xFE,0x18,0x23,0xFF,0xFF,0x88,0x0F,0xFF,0xFF,0xE0,0x27,0xFF,0xFF,0xC0,0x39,0xFF,0xFF,0x18,0x3E,0x00,0x00,0x78,0x3F,0x00,0x01,0xF8,0x3F,0x00,0x01,0xF8,0x3F,0x00,0x01,0xF8,0x3F,0x00,0x01,0xF8,0x3F,0x00,0x01,0xF8,0x3F,0x00,0x01,0xF8,0x3F,0x00,0x01,0xF8,0x3F,0x00,0x01,0xF8,0x3F,0x00,0x01,0xF8,0x3F,0x00,0x01,0xF8,0x3F,0x00,0x01,0xF8,0x3F,0x00,0x01,0xF8,0x3F,0x00,0x01,0xF8,0x3F,0x00,0x01,0xF8,0x1E,0x00,0x00,0xF0,0x0C,0xFF,0xFE,0x60,0x01,0xFF,0xFF,0x00,0x03,0xFF,0xFF,0x80,0x01,0xFF,0xFF,0x00,0x00,0xFF,0xFE,0x00,0x00,0x00,0x00,0x00,0x00,0x00,0x00,0x00,  // 8
0x00,0x00,0x00,0x00,0x00,0x00,0x00,0x00,0x00,0xFF,0xFE,0x00,0x01,0xFF,0xFF,0x00,0x03,0xFF,0xFF,0x80,0x01,0xFF,0xFF,0x60,0x0C,0xFF,0xFE,0xF0,0x1E,0x00,0x01,0xF8,0x3F,0x00,0x01,0xF8,0x3F,0x00,0x01,0xF8,0x3F,0x00,0x01,0xF8,0x3F,0x00,0x01,0xF8,0x3F,0x00,0x01,0xF8,0x3F,0x00,0x01,0xF8,0x3F,0x00,0x01,0xF8,0x3F,0x00,0x01,0xF8,0x3F,0x00,0x01,0xF8,0x3F,0x00,0x01,0xF8,0x3F,0x00,0x01,0xF8,0x3F,0x00,0x01,0xF8,0x3F,0x00,0x01,0xF8,0x3E,0x00,0x00,0x78,0x39,0xFF,0xFE,0x18,0x23,0xFF,0xFF,0x88,0x0F,0xFF,0xFF,0xE0,0x07,0xFF,0xFF,0xC0,0x01,0xFF,0xFF,0x18,0x00,0x00,0x00,0x78,0x00,0x00,0x01,0xF8,0x00,0x00,0x01,0xF8,0x00,0x00,0x01,0xF8,0x00,0x00,0x01,0xF8,0x00,0x00,0x01,0xF8,0x00,0x00,0x01,0xF8,0x00,0x00,0x01,0xF8,0x00,0x00,0x01,0xF8,0x00,0x00,0x01,0xF8,0x00,0x00,0x01,0xF8,0x00,0x00,0x01,0xF8,0x00,0x00,0x01,0xF8,0x00,0x00,0x01,0xF8,0x00,0x00,0x01,0xF8,0x00,0x00,0x00,0xF0,0x00,0xFF,0xFE,0x60,0x01,0xFF,0xFF,0x00,0x03,0xFF,0xFF,0x80,0x01,0xFF,0xFF,0x00,0x00,0xFF,0xFE,0x00,0x00,0x00,0x00,0x00,0x00,0x00,0x00,0x00,  // 9
};

/* USER CODE END PV */

void SystemClock_Config(void);

int main(void)
{

  /* MCU Configuration--------------------------------------------------------*/

  /* Reset of all peripherals, Initializes the Flash interface and the Systick. */
  HAL_Init();

  /* Configure the system clock */
  SystemClock_Config();

  /* USER CODE BEGIN SysInit */
  srand (HAL_GetTick());
  /* USER CODE END SysInit */

  /* Initialize all configured peripherals */
  MX_GPIO_Init();
  MX_FSMC_Init();
  /* USER CODE BEGIN 2 */

  InitLCD();
  setFont(SmallFont);
  uint16_t buf[478];
  uint16_t x, x2;
  uint16_t y, y2;
  uint16_t r;
  sprintf(buf,"%d",x);
// Clear the screen and draw the frame

  /* USER CODE END 2 */

  /* Infinite loop */
  while (1)
  {

    /* USER CODE BEGIN 3 */
	//******************************************************************************************************************
	LCD_clrScr();
	setColorRGB(255, 0, 0);
	fillRect(0, 0, 479, 13);
	setColorRGB(64, 64, 64);
	fillRect(0, 306, 479, 319);
	setColorRGB(255, 255, 255);
	setBackColorRGB(255, 0, 0);
	print("* Universal Color TFT Display Library *", CENTER, 1,0);
	setBackColorRGB(64, 64, 64);
	setColorRGB(255,255,0);
	print("<http://electronics.henningkarlsen.com>", CENTER, 307,0);
    setColorRGB(0, 0, 255);
    drawRect(0, 14, 479, 305);
// Draw crosshairs
    setColorRGB(0, 0, 255);
    setBackColorRGB(0, 0, 0);
    drawLine(239, 15, 239, 304);
    drawLine(1, 159, 478, 159);
    for (int i=9; i<470; i+=10)
    	drawLine(i, 157, i, 161);
    for (int i=19; i<220; i+=10)
    	drawLine(237, i, 241, i);
// Draw sin-, cos- and tan-lines
    setColorRGB(0,255,255);
    print("Sin", 5, 15,0);
    for (int i=1; i<478; i++){
      drawPixel(i,159+(sin(((i*1.13)*3.14)/180)*95));
    }
    setColorRGB(255,0,0);
    print("Cos", 5, 27,0);
    for (int i=1; i<478; i++){
      drawPixel(i,159+(cos(((i*1.13)*3.14)/180)*95));
    }
    setColorRGB(255,255,0);
    print("Tan", 5, 39,0);
    for (int i=1; i<478; i++){
      drawPixel(i,159+(tan(((i*1.13)*3.14)/180)));
    }
    HAL_Delay(1000);
    setColorRGB(0,0,0);
    fillRect(1,15,478,304);
    setColorRGB(0, 0, 255);
    setBackColorRGB(0, 0, 0);
    drawLine(239, 15, 239, 304);
    drawLine(1, 159, 478, 159);
// Draw a moving sinewave
     x=1;
      for (int i=1; i<(478*15); i++){
        x++;
        if (x==479)
          x=1;
        if (i>479)
        {
          if ((x==239)||(buf[x-1]==159))
          	setColorRGB(0,0,255);
          else
          	setColorRGB(0,0,0);
          drawPixel(x,buf[x-1]);
        }
        setColorRGB(0,255,255);
        y=159+(sin(((i*0.7)*3.14)/180)*(90-(i / 100)));
        drawPixel(x,y);
        buf[x-1]=y;
      }
 //-------------------------------------------------------------------------------------------------
    HAL_Delay(1000);
    setColorRGB(0,0,0);
    fillRect(1,15,478,304);
// Draw some filled rectangles
    for (int i=1; i<6; i++){
      switch (i)
      {
        case 1:
          setColorRGB(255,0,255);
          break;
        case 2:
          setColorRGB(255,0,0);
          break;
        case 3:
          setColorRGB(0,255,0);
          break;
        case 4:
          setColorRGB(0,0,255);
          break;
        case 5:
          setColorRGB(255,255,0);
          break;
      }
      fillRect(150+(i*20), 70+(i*20), 210+(i*20), 130+(i*20));
    }
    HAL_Delay(1000);
    setColorRGB(0,0,0);
    fillRect(1,15,478,304);
// Draw some filled, rounded rectangles
    for (int i=1; i<6; i++){
      switch (i)
      {
        case 1:
          setColorRGB(255,0,255);
          break;
        case 2:
          setColorRGB(255,0,0);
          break;
        case 3:
          setColorRGB(0,255,0);
          break;
        case 4:
          setColorRGB(0,0,255);
          break;
        case 5:
          setColorRGB(255,255,0);
          break;
      }
      fillRoundRect(270-(i*20), 70+(i*20), 330-(i*20), 130+(i*20));
    }
    HAL_Delay(1000);
    setColorRGB(0,0,0);
    fillRect(1,15,478,304);
// Draw some filled circles
    for (int i=1; i<6; i++){
      switch (i)
      {
        case 1:
      	  setColorRGB(255,0,255);
          break;
        case 2:
       	  setColorRGB(255,0,0);
          break;
        case 3:
          setColorRGB(0,255,0);
          break;
        case 4:
          setColorRGB(0,0,255);
           break;
        case 5:
          setColorRGB(255,255,0);
          break;
      }
      fillCircle(180+(i*20),100+(i*20), 30);
    }
    HAL_Delay(1000);
    setColorRGB(0,0,0);
    fillRect(1,15,478,304);
// Draw some lines in a pattern
    setColorRGB(255,0,0);
    for (int i=15; i<304; i+=5){
    	drawLine(1, i, (i*1.6)-10, 304);
     }
     setColorRGB(255,0,0);
     for (int i=304; i>15; i-=5){
    	 drawLine(478, i, (i*1.6)-11, 15);
     }
     setColorRGB(0,255,255);
     for (int i=304; i>15; i-=5)      {
    	 drawLine(1, i, 491-(i*1.6), 15);
     }
     setColorRGB(0,255,255);
     for (int i=15; i<304; i+=5){
    	 drawLine(478, i, 490-(i*1.6), 304);
     }
     HAL_Delay(1000);
     setColorRGB(0,0,0);
     fillRect(1,15,478,304);
// Draw some random circles
     for (int i=0; i<100; i++){
    	  setColorRGB(rand()%255+1, rand()%255+1, rand()%255+1);
    	  x=32+rand()%416+1;
    	  y=45+rand()%226+1;
    	  r=rand()%30+1;
    	  drawCircle(x, y, r);
     }
     HAL_Delay(1000);
     setColorRGB(0,0,0);
     fillRect(1,15,478,304);
// Draw some random rectangles
     for (int i=0; i<100; i++){
    	   setColorRGB(random()%255+1, random()%255+1, random()%255+1);
    	   x=2+random()%476+1;
    	   y=16+random()%289+1;
    	   x2=2+random()%476+1;
    	   y2=16+random()%289+1;
    	   drawRect(x, y, x2, y2);
     }
     HAL_Delay(1000);
     setColorRGB(0,0,0);
     fillRect(1,15,478,304);
// Draw some random rounded rectangles
     for (int i=0; i<100; i++){
    	   setColorRGB(random()%255+1, random()%255+1, random()%255+1);
    	   x=2+random()%476+1;
    	   y=16+random()%289+1;
    	   x2=2+random()%476+1;
    	   y2=16+random()%289+1;
    	   drawRoundRect(x, y, x2, y2);
     }
	 HAL_Delay(1000);
	 setColorRGB(0,0,0);
     fillRect(1,15,478,304);
	 for (int i=0; i<100; i++){
		   setColorRGB(random()%255+1, random()%255+1, random()%255+1);
		   x=2+random()%476+1;
		   y=16+random()%289+1;
		   x2=2+random()%476+1;
		   y2=16+random()%289+1;
		   drawLine(x, y, x2, y2);
     }
	 HAL_Delay(1000);
	 setColorRGB(0,0,0);
     fillRect(1,15,478,304);
     for (int i=0; i<10000; i++){
    	   setColorRGB(random()%255+1, random()%255+1, random()%255+1);
    	   drawPixel(2+random()%476+1, 16+random()%289+1);
     }
     HAL_Delay(1000);
     setColorRGB(0, 0, 255);
     fillScr(f_color);
     setColorRGB(255, 0, 0);
     fillRoundRect(160, 70, 319, 169);
     setColorRGB(255, 255, 255);
     setBackColorRGB(255, 0, 0);
     print("That's it!", CENTER, 93,0);
     print("Restarting in a", CENTER, 119,0);
     print("few seconds...", CENTER, 132,0);
     setColorRGB(0, 255, 0);
     setBackColorRGB(0, 0, 255);
     print("Runtime: (msecs)", CENTER, 290,0);
     printNumI(0x7fffffff, CENTER, 305,0,' ');
     HAL_Delay (5000);
  }
  /* USER CODE END 3 */
}

void SystemClock_Config(void)
{
  RCC_OscInitTypeDef RCC_OscInitStruct = {0};
  RCC_ClkInitTypeDef RCC_ClkInitStruct = {0};

  /** Initializes the RCC Oscillators according to the specified parameters
  * in the RCC_OscInitTypeDef structure.
  */
  RCC_OscInitStruct.OscillatorType = RCC_OSCILLATORTYPE_HSE;
  RCC_OscInitStruct.HSEState = RCC_HSE_ON;
  RCC_OscInitStruct.HSEPredivValue = RCC_HSE_PREDIV_DIV1;
  RCC_OscInitStruct.HSIState = RCC_HSI_ON;
  RCC_OscInitStruct.PLL.PLLState = RCC_PLL_ON;
  RCC_OscInitStruct.PLL.PLLSource = RCC_PLLSOURCE_HSE;
  RCC_OscInitStruct.PLL.PLLMUL = RCC_PLL_MUL9;
  if (HAL_RCC_OscConfig(&RCC_OscInitStruct) != HAL_OK)
  {
    Error_Handler();
  }
  /** Initializes the CPU, AHB and APB buses clocks
  */
  RCC_ClkInitStruct.ClockType = RCC_CLOCKTYPE_HCLK|RCC_CLOCKTYPE_SYSCLK
                              |RCC_CLOCKTYPE_PCLK1|RCC_CLOCKTYPE_PCLK2;
  RCC_ClkInitStruct.SYSCLKSource = RCC_SYSCLKSOURCE_PLLCLK;
  RCC_ClkInitStruct.AHBCLKDivider = RCC_SYSCLK_DIV1;
  RCC_ClkInitStruct.APB1CLKDivider = RCC_HCLK_DIV2;
  RCC_ClkInitStruct.APB2CLKDivider = RCC_HCLK_DIV1;

  if (HAL_RCC_ClockConfig(&RCC_ClkInitStruct, FLASH_LATENCY_2) != HAL_OK)
  {
    Error_Handler();
  }
}

void Error_Handler(void)
{
}

/************************ (C) COPYRIGHT STMicroelectronics *****END OF FILE****/
